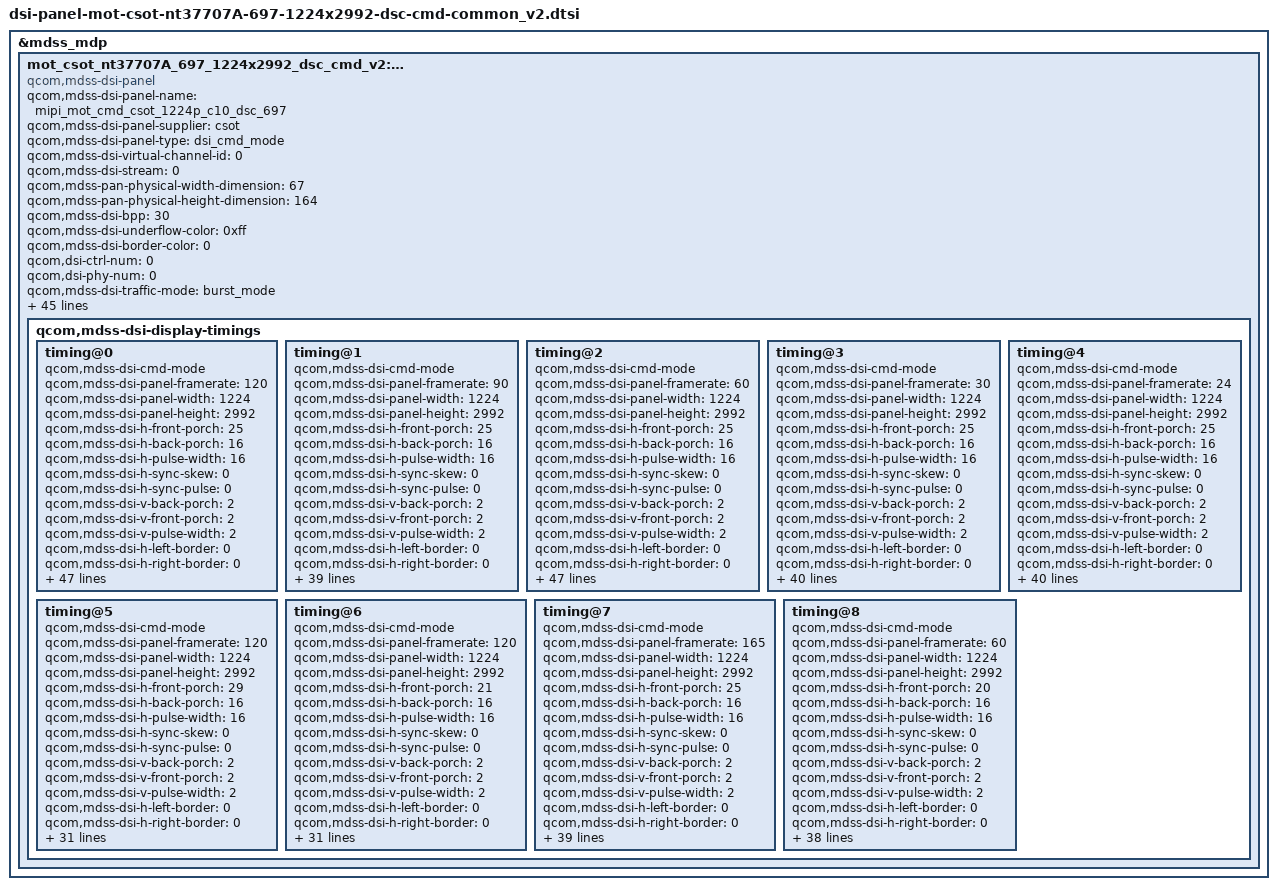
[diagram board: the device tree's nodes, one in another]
/* Copyright (c) 2019-2020, The Linux Foundation. All rights reserved.
 *
 * This program is free software; you can redistribute it and/or modify
 * it under the terms of the GNU General Public License version 2 and
 * only version 2 as published by the Free Software Foundation.
 *
 * This program is distributed in the hope that it will be useful,
 * but WITHOUT ANY WARRANTY; without even the implied warranty of
 * MERCHANTABILITY or FITNESS FOR A PARTICULAR PURPOSE.  See the
 * GNU General Public License for more details.
 */
&mdss_mdp {
mot_csot_nt37707A_697_1224x2992_dsc_cmd_v2: qcom,mdss_dsi_mot_csot_nt37707A_697_1224x2992_dsc_cmd_v2 {
compatible = "qcom,mdss-dsi-panel";
qcom,mdss-dsi-panel-name = "mipi_mot_cmd_csot_1224p_c10_dsc_697";
qcom,mdss-dsi-panel-supplier = "csot";
qcom,mdss-dsi-panel-type = "dsi_cmd_mode";
qcom,mdss-dsi-virtual-channel-id = <0>;
qcom,mdss-dsi-stream = <0>;
qcom,mdss-pan-physical-width-dimension = <67>;
qcom,mdss-pan-physical-height-dimension = <164>;
qcom,mdss-dsi-bpp = <30>;
qcom,mdss-dsi-underflow-color = <0xff>;
qcom,mdss-dsi-border-color = <0>;

qcom,dsi-ctrl-num = <0>;
qcom,dsi-phy-num = <0>;

qcom,mdss-dsi-traffic-mode = "burst_mode";
qcom,mdss-dsi-bllp-eof-power-mode;
qcom,mdss-dsi-bllp-power-mode;
qcom,mdss-dsi-lane-0-state;
qcom,mdss-dsi-lane-1-state;
qcom,mdss-dsi-lane-2-state;
qcom,mdss-dsi-lane-3-state;

qcom,mdss-dsi-dma-trigger = "trigger_sw";
qcom,mdss-dsi-mdp-trigger = "none";
qcom,mdss-dsi-reset-sequence = <0 3>, <1 1>, <0 1>, <1 20>;
qcom,mdss-dsi-lp11-init;
qcom,mdss-dsi-tx-eot-append;
qcom,mdss-dsi-te-pin-select = <1>;
qcom,mdss-dsi-te-dcs-command = <1>;
qcom,mdss-dsi-te-using-te-pin;

//qcom,bklt-dcs-2bytes-enabled;
qcom,mdss-dsi-bl-min-level = <4>;
qcom,mdss-dsi-bl-max-level = <14056>;
qcom,mdss-dsi-bl-pmic-control-type = "bl_ctrl_dcs";

qcom,mdss-dsi-panel-hdr-enabled;
qcom,mdss-dsi-panel-hdr-color-primaries = <14500 15500 32000
	        17000 15500 30000 8000 3000>;
qcom,mdss-dsi-panel-peak-brightness = <4200000>;

qcom,mdss-dsi-panel-blackness-level = <3230>;

qcom,mdss-dsi-dc-off-command = [
		39 00 00 40 00 00 02 6F 01
		39 00 00 40 00 00 02 8B 00
		39 00 00 00 00 00 03 6D 00 00
		];

qcom,mdss-dsi-dc-off-command-state = "dsi_hs_mode";
qcom,mdss-dsi-dc-on-command = [
		39 00 00 40 00 00 02 6F 01
		39 00 00 40 00 00 02 8B 81
		39 00 00 00 00 00 03 6D 00 00
		];
qcom,mdss-dsi-dc-on-command-state = "dsi_hs_mode";
//qcom,mdss-dsi-nt37705-dc-detect-fps;
qcom,check_pcd;
qcom,pcd-reg-read-enabled;
qcom,pcd-reg-check-before-read;
qcom,mdss-dsi-panel-pcd-reg-read-length = <1>;
qcom,mdss-dsi-panel-pcd-reg-mask = <0xFF>;
qcom,mdss-dsi-panel-pcd-reg-command = [06 01 00 01 00 00 01 D0];
qcom,mdss-dsi-panel-pcd-reg-pass-array-size = <4>;
qcom,mdss-dsi-panel-pcd-reg-pass-array = <0x80 0x81 0x82 0x83>;
qcom,mdss-dsi-panel-pcd-reg-read-delay-ms = <150>;
qcom,mdss-dsi-panel-pcd-reg-seq-interval = <30>; //pcd reg read seq interval per screen on.
qcom,mdss-dsi-panel-pcd-check-time-interval-in-minutes = <480>; //480 minutes/8hours for pcd reg read time interval

qcom,mdss-dsi-display-timings {
	timing@0{
		qcom,mdss-dsi-cmd-mode;
		qcom,mdss-dsi-panel-framerate = <120>;
		qcom,mdss-dsi-panel-width = <1224>;
		qcom,mdss-dsi-panel-height = <2992>;
		qcom,mdss-dsi-h-front-porch = <25>;
		qcom,mdss-dsi-h-back-porch = <16>;
		qcom,mdss-dsi-h-pulse-width = <16>;
		qcom,mdss-dsi-h-sync-skew = <0>;
		qcom,mdss-dsi-h-sync-pulse = <0>;
		qcom,mdss-dsi-v-back-porch = <2>;
		qcom,mdss-dsi-v-front-porch = <2>;
		qcom,mdss-dsi-v-pulse-width = <2>;
		qcom,mdss-dsi-h-left-border = <0>;
		qcom,mdss-dsi-h-right-border = <0>;
		qcom,mdss-dsi-v-top-border = <0>;
		qcom,mdss-dsi-v-bottom-border = <0>;
	        qcom,mdss-dsi-panel-jitter = <0x20 0xa>;
		qcom,mdss-dsi-timing-switch-command = [
			39 00 00 40 00 00 02 6B 00
			39 00 00 40 00 00 06 F0 55 AA 52 08 00
			39 00 00 40 00 00 02 6F CC
			39 00 00 40 00 00 02 B2 00 //exit MAFR
			39 00 00 40 00 00 02 6F 02
			39 00 00 40 00 00 02 8C 10
			39 00 00 40 00 00 02 8C 00
			39 00 00 40 00 00 02 6F 04
			39 00 00 40 00 00 02 35 00 //TE1=0
			39 00 00 40 00 00 02 53 20 //DBV Diming Disable
			39 00 00 00 00 00 02 2F 02 //120hz
		];
		qcom,mdss-dsi-on-command = [
			39 00 00 40 00 00 06 F0 55 AA 52 08 00
			39 00 00 40 00 00 02 6F 04
			39 00 00 40 00 00 05 C6 33 A3 33 33
			39 00 00 40 00 00 06 F0 55 AA 52 08 01
			39 00 00 40 00 00 02 6F 2F
			39 00 00 40 00 00 02 C3 44
			39 00 00 40 00 00 02 6F 00
			39 00 00 40 00 00 02 C3 DD
			39 00 00 40 00 00 02 6F 04
			39 00 00 40 00 00 02 C3 07
			39 00 00 40 00 00 02 6F 09
			39 00 00 40 00 00 02 C3 07
			39 00 00 40 00 00 06 F0 55 AA 52 08 00
			39 00 00 40 00 00 02 6F 04
			39 00 00 40 00 00 02 B1 07
			39 00 00 40 00 00 02 68 20
			39 00 00 40 00 00 06 F0 55 AA 52 08 09
			39 00 00 40 00 00 02 BD 05
			39 00 00 40 00 00 02 6F 10
			39 00 00 40 00 00 02 C1 00
			39 00 00 40 00 00 02 6F 11
			39 00 00 40 00 00 03 C1 00 0A
			39 00 00 40 00 00 02 6F 13
			39 00 00 40 00 00 03 C1 00 00
			39 00 00 40 00 00 02 6F 00
			39 00 00 40 00 00 06 C6 8A 8D 8D 90 90
			39 00 00 40 00 00 02 6F 05
			39 00 00 40 00 00 06 C6 89 85 83 8A 8A
			39 00 00 40 00 00 02 6F 0A
			39 00 00 40 00 00 06 C6 8A 83 89 84 8A
			39 00 00 40 00 00 02 6F 0F
			39 00 00 40 00 00 06 C6 85 83 83 84 85
			39 00 00 40 00 00 02 6F 14
			39 00 00 40 00 00 06 C6 84 84 85 84 83
			39 00 00 40 00 00 02 6F 19
			39 00 00 40 00 00 06 C6 83 84 83 84 83
			39 00 00 40 00 00 02 6F 1E
			39 00 00 40 00 00 06 C6 8A 8D 8D 90 90
			39 00 00 40 00 00 02 6F 23
			39 00 00 40 00 00 06 C6 89 85 83 8A 8A
			39 00 00 40 00 00 02 6F 28
			39 00 00 40 00 00 06 C6 8A 83 89 84 8A
			39 00 00 40 00 00 02 6F 2D
			39 00 00 40 00 00 06 C6 85 83 83 84 85
			39 00 00 40 00 00 02 6F 32
			39 00 00 40 00 00 06 C6 84 84 85 84 83
			39 00 00 40 00 00 02 6F 37
			39 00 00 40 00 00 06 C6 83 84 83 84 83
			39 00 00 40 00 00 02 6F 3C
			39 00 00 40 00 00 06 C6 8A 8D 8D 90 90
			39 00 00 40 00 00 02 6F 41
			39 00 00 40 00 00 06 C6 89 85 83 8A 8A
			39 00 00 40 00 00 02 6F 46
			39 00 00 40 00 00 06 C6 85 83 89 84 8A
			39 00 00 40 00 00 02 6F 4B
			39 00 00 40 00 00 06 C6 8A 83 83 84 85
			39 00 00 40 00 00 02 6F 50
			39 00 00 40 00 00 06 C6 84 84 85 84 83
			39 00 00 40 00 00 02 6F 55
			39 00 00 40 00 00 06 C6 83 84 83 84 83
			39 00 00 40 00 00 06 F0 55 AA 52 08 00
			39 00 00 40 00 00 02 6F 0D
			39 00 00 40 00 00 02 C2 1A
			39 00 00 40 00 00 06 F0 55 AA 52 08 04
			39 00 00 40 00 00 02 B1 00
			39 00 00 40 00 00 02 6F 0A
			39 00 00 40 00 00 02 B1 20
			39 00 00 40 00 00 02 6F 07
			39 00 00 40 00 00 04 B1 00 00 00
			39 00 00 40 00 00 02 6F 0B
			39 00 00 40 00 00 02 B1 00
			39 00 00 40 00 00 02 6F 06
			39 00 00 40 00 00 02 8D 05
			39 00 00 40 00 00 02 6F 01
			39 00 00 40 00 00 02 8D 20
			39 00 00 40 00 00 02 5A 01
			39 00 00 40 00 00 06 F0 55 AA 52 08 00
			39 00 00 40 00 00 02 6F 31
			39 00 00 40 00 00 04 C0 00 23 00
			39 00 00 40 00 00 02 6F 35
			39 00 00 40 00 00 04 C0 44 41 44
			39 00 00 40 00 00 06 F0 55 AA 52 08 04
			39 00 00 40 00 00 02 C0 20
			39 00 00 40 00 00 05 FF AA 55 A5 80
			39 00 00 40 00 00 02 6F 07
			39 00 00 40 00 00 02 F8 4D
			39 00 00 40 00 00 02 6F 23
			39 00 00 40 00 00 02 F8 4D
			39 00 00 40 00 00 05 FF AA 55 A5 81
			39 00 00 40 00 00 02 6F 21
			39 00 00 40 00 00 02 F5 03
			39 00 00 40 00 00 02 6F 43
			39 00 00 40 00 00 19 F5 01 02 01 04 00 01 02 00 00 00 43 02 00 00 10 00 00 10 05 00 11 31 12 11
			39 00 00 40 00 00 02 6F 1D
			39 00 00 40 00 00 04 FB 64 07 80
			39 00 00 40 00 00 02 6F 07
			39 00 00 40 00 00 02 FC 04
			39 00 00 40 00 00 02 6F 30
			39 00 00 40 00 00 02 FE 20
			39 00 00 40 00 00 05 FF AA 55 A5 84
			39 00 00 40 00 00 02 6F 9A
			39 00 00 40 00 00 02 F3 0F
			39 00 00 40 00 00 02 6F 9F
			39 00 00 40 00 00 02 F4 00
			39 00 00 40 00 00 02 6F E9
			39 00 00 40 00 00 02 F4 03
			39 00 00 40 00 00 02 6F 28
			39 00 00 40 00 00 02 F8 00
			39 00 00 40 00 00 05 FF AA 55 A5 81
			39 00 00 40 00 00 02 6F 0F
			39 00 00 40 00 00 02 F5 0E
			39 00 00 40 00 00 06 F0 55 AA 52 08 00
			39 00 00 40 00 00 02 6F 78
			39 00 00 40 00 00 18 B0 10 00 2A 00 C2 01 DA 03 7C 05 B1 08 80 0B EE 0F FF 05 55 05 56 05 55
			39 00 00 40 00 00 02 6F 6F
			39 00 00 40 00 00 07 B0 02 64 04 C8 02 64
			39 00 00 40 00 00 06 F0 55 AA 52 08 08
			39 00 00 40 00 00 17 C1 8D FF DD FF FF DD FF FF DD FF FF DD FF FF EE FF FF AA 7C 1E 0E FF
			39 00 00 40 00 00 02 6F 23
			39 00 00 40 00 00 15 C1 0D FF DD FF FF DD FF FF DD FF FF DD FF FF EE FF FF AA 7C 1E
			39 00 00 40 00 00 02 6F 37
			39 00 00 40 00 00 15 C1 0D FF DD FF FF DD FF FF DD FF FF DD FF FF EE FF FF FF FF FF
			39 00 00 40 00 00 02 6F 4B
			39 00 00 40 00 00 15 C1 0D FF DD FF FF DD FF FF DD FF FF DD FF FF EE FF FF AA 7C 1E
			39 00 00 40 00 00 02 6F 5F
			39 00 00 40 00 00 15 C1 0D FF DD FF FF DD FF FF DD FF FF DD FF FF EE FF FF FF FF FF
			39 00 00 40 00 00 02 6F 73
			39 00 00 40 00 00 15 C1 0D FF DD FF FF DD FF FF DD FF FF DD FF FF EE FF FF AA 7C 1E
			39 00 00 40 00 00 11 BA 00 04 03 A4 03 A4 05 B8 05 B8 07 D8 07 D8 0A 84
			39 00 00 40 00 00 02 6F 10
			39 00 00 40 00 00 11 BA 0A 84 0D C3 0D C3 0D C4 0D C4 1D 24 1D 24 2C 50
			39 00 00 40 00 00 02 6F 20
			39 00 00 40 00 00 0d BA 2C 50 36 E8 36 E8 3A FE 3A FE 3F FC
			39 00 00 40 00 00 02 6F 20
			39 00 00 40 00 00 04 C1 04 52 CD
			39 00 00 40 00 00 02 6F 1D
			39 00 00 40 00 00 04 C1 00 80 FF
			39 00 00 40 00 00 02 6F 07
			39 00 00 40 00 00 02 51 00
			39 00 00 40 00 00 05 FF AA 55 A5 81
			39 00 00 40 00 00 02 6F 02
			39 00 00 40 00 00 02 F9 04
			39 00 00 40 00 00 05 FF AA 55 A5 81
			39 00 00 40 00 00 02 6F 0D
			39 00 00 40 00 00 02 FB 80
			39 00 00 40 00 00 05 FF AA 55 A5 81
			39 00 00 40 00 00 02 6F 10
			39 00 00 40 00 00 02 FB 40
			39 00 00 40 00 00 05 FF AA 55 A5 81
			39 00 00 40 00 00 02 6F 0C
			39 00 00 40 00 00 02 FD 08
			39 00 00 40 00 00 05 FF AA 55 A5 81
			39 00 00 40 00 00 02 6F 05
			39 00 00 40 00 00 03 FE 3C 3C
			39 00 00 40 00 00 05 FF AA 55 A5 80
			39 00 00 40 00 00 02 6F 0A
			39 00 00 40 00 00 06 F6 70 70 70 70 70
			39 00 00 40 00 00 05 2A 00 00 04 C7
			39 00 00 40 00 00 05 2B 00 00 0B AF
			39 00 00 40 00 00 02 2F 02
			39 00 00 40 00 00 03 5F 00 00
			39 00 00 40 00 00 02 35 00
			39 00 00 40 00 00 02 6F 02
			39 00 00 40 00 00 02 8C 10
			39 00 00 40 00 00 02 8C 00
			39 00 00 40 00 00 02 6F 04
			39 00 00 40 00 00 02 35 00
			39 00 00 40 00 00 03 51 00 00
			39 00 00 40 00 00 02 6F 04
			39 00 00 40 00 00 03 51 00 00
			39 00 00 40 00 00 02 53 20
			39 00 00 40 00 00 02 90 03
			39 00 00 40 00 00 02 6F 01
			39 00 00 40 00 00 02 90 43
			39 00 00 00 00 00 13 91 AB 28 00 10 C2 00 02 32 01 9C 00 08 06 67 05 9C 10 F0
                	05 00 00 00 78 00 01 11
                	05 00 00 00 00 00 01 29];	/* display on */
		qcom,mdss-dsi-off-command = [
			05 00 00 00 00 00 01 28		/* display_off */
			05 00 00 00 64 00 01 10];	/* enter sleep mode */

		qcom,mdss-dsi-on-command-state = "dsi_lp_mode";
		qcom,mdss-dsi-off-command-state = "dsi_lp_mode";
		qcom,mdss-dsi-timing-switch-command-state =
			"dsi_lp_mode";
		qcom,compression-mode = "dsc";
		/* Why QCOM doesn't use this, even it used 2 encoder
		 * as for that dsi_sw43404_amoled_cmd, for ex */
		/* qcom,mdss-dsc-encoders = <2>; */
		qcom,mdss-dsc-version = <0x11>;
		qcom,mdss-dsc-slice-height = <16>;
		qcom,mdss-dsc-slice-width = <612>;
		qcom,mdss-dsc-slice-per-pkt = <2>;
		qcom,mdss-dsc-bit-per-component = <10>;
		qcom,mdss-dsc-bit-per-pixel = <8>;
		qcom,mdss-dsc-block-prediction-enable;
		qcom,mdss-dsc-novateck-ic;
		qcom,mdss-dsi-pcd-check-enable-command = [
			39 00 00 40 00 00 06 F0 55 AA 52 08 06
			39 00 00 40 00 00 03 B1 35 35
			39 00 00 40 00 00 02 6F 01
			39 00 00 40 00 00 02 B2 37
			39 00 00 40 00 00 03 B7 35 35
			39 00 00 40 00 00 02 6F 01
			39 00 00 40 00 00 02 B8 37
			39 00 00 40 00 00 05 FF AA 55 A5 80
			39 00 00 40 00 00 02 6F 12
			39 00 00 40 00 00 04 F4 01 0C 11
			39 00 00 00 00 00 02 9B 00];

		qcom,mdss-dsi-pcd-check-enable-command-state = "dsi_hs_mode";
		qcom,mdss-dsi-pcd-check-disable-command = [
			39 00 00 40 00 00 06 F0 55 AA 52 08 06
			39 00 00 40 00 00 03 B1 37 37
			39 00 00 40 00 00 02 6F 01
			39 00 00 40 00 00 02 B2 36
			39 00 00 40 00 00 03 B7 37 37
			39 00 00 40 00 00 02 6F 01
			39 00 00 40 00 00 02 B8 36
			39 00 00 40 00 00 05 FF AA 55 A5 80
			39 00 00 40 00 00 02 6F 12
			39 00 00 40 00 00 04 F4 00 00 00
			39 00 00 00 00 00 02 9B 01];
		qcom,mdss-dsi-pcd-check-disable-command-state = "dsi_hs_mode";
		qcom,mdss-dsi-pcd-check-in-enable-command = [
			39 00 00 40 00 00 06 F0 55 AA 52 08 01
			39 00 00 00 00 00 03 D0 00 80
			];
		qcom,mdss-dsi-pcd-check-in-enable-command-state = "dsi_hs_mode";
		qcom,mdss-dsi-pcd-check-in-disable-command = [
			39 00 00 40 00 00 06 F0 55 AA 52 08 01
			39 00 00 00 00 00 03 D0 00 00
			];
		qcom,mdss-dsi-pcd-check-in-disable-command-state = "dsi_hs_mode";
		qcom,mdss-dsi-lp1-command = [
			39 00 00 40 00 00 02 6B 00
			39 00 00 40 00 00 06 F0 55 AA 52 08 00
			39 00 00 40 00 00 02 6F CC
			39 00 00 40 00 00 02 B2 00 //exit MAFR
			39 00 00 40 00 00 02 6F 02
			39 00 00 40 00 00 02 8C 10
			39 00 00 40 00 00 02 8C 00
			39 00 00 40 00 00 02 6F 04
			39 00 00 40 00 00 02 35 00 //TE1=0
			39 00 00 40 00 00 02 53 20 //DBV Diming Disable
			39 00 00 00 00 00 02 2F 02 //120hz
		];
		qcom,mdss-dsi-lp1-command-state =
			"dsi_lp_mode";
		qcom,mdss-dsi-lp2-command = [
			39 00 00 40 00 00 02 6B 00
			39 00 00 40 00 00 06 F0 55 AA 52 08 00
			39 00 00 40 00 00 02 6F CC
			39 00 00 40 00 00 02 B2 00 //exit MAFR
			39 00 00 40 00 00 02 6F 04
			39 00 00 40 00 00 02 35 00 //TE = 1
			39 00 00 40 00 00 02 53 20 //DBV Diming Enable
			39 00 00 40 00 00 02 5A 00
			39 00 00 40 00 00 02 6F 06
			39 00 00 40 00 00 02 6D 00
			39 00 00 40 00 00 02 2F 30
			39 00 00 40 00 00 03 6D 04 00
			39 00 00 40 00 00 02 6F 02
			39 00 00 40 00 00 02 8C 10
			39 00 00 00 00 00 02 8C 00
		];
		qcom,mdss-dsi-lp2-command-state =
			"dsi_lp_mode";
		qcom,mdss-dsi-nolp-command = [
			39 00 00 40 00 00 02 6B 00
			39 00 00 40 00 00 06 F0 55 AA 52 08 00
			39 00 00 40 00 00 02 6F CC
			39 00 00 40 00 00 02 B2 00 //exit MAFR
			39 00 00 40 00 00 02 6F 02
			39 00 00 40 00 00 02 8C 10
			39 00 00 40 00 00 02 8C 00
			39 00 00 40 00 00 02 6F 04
			39 00 00 40 00 00 02 35 00 //TE1=0
			39 00 00 40 00 00 02 53 20 //DBV Diming Disable
			39 00 00 00 00 00 02 2F 02 //120hz
		];
		qcom,mdss-dsi-nolp-command-state =
			"dsi_lp_mode";
	};

	timing@1{
		qcom,mdss-dsi-cmd-mode;
		qcom,mdss-dsi-panel-framerate = <90>;
		qcom,mdss-dsi-panel-width = <1224>;
		qcom,mdss-dsi-panel-height = <2992>;
		qcom,mdss-dsi-h-front-porch = <25>;
		qcom,mdss-dsi-h-back-porch = <16>;
		qcom,mdss-dsi-h-pulse-width = <16>;
		qcom,mdss-dsi-h-sync-skew = <0>;
		qcom,mdss-dsi-h-sync-pulse = <0>;
		qcom,mdss-dsi-v-back-porch = <2>;
		qcom,mdss-dsi-v-front-porch = <2>;
		qcom,mdss-dsi-v-pulse-width = <2>;
		qcom,mdss-dsi-h-left-border = <0>;
		qcom,mdss-dsi-h-right-border = <0>;
		qcom,mdss-dsi-v-top-border = <0>;
		qcom,mdss-dsi-v-bottom-border = <0>;
	        qcom,mdss-dsi-panel-jitter = <0x20 0xa>;
		qcom,mdss-dsi-timing-switch-command = [
			39 00 00 40 00 00 02 6B 00
			39 00 00 40 00 00 06 F0 55 AA 52 08 00
			39 00 00 40 00 00 02 6F CC
			39 00 00 40 00 00 02 B2 00 //exit MAFR
			39 00 00 40 00 00 02 6F 02
			39 00 00 40 00 00 02 8C 10
			39 00 00 40 00 00 02 8C 00
			39 00 00 40 00 00 02 6F 04
			39 00 00 40 00 00 02 35 00 //TE1=0
			39 00 00 40 00 00 02 53 20 //DBV Diming Disable
			39 00 00 00 0B 00 02 2F 04 //90hz
		];
		qcom,mdss-dsi-on-command = [
			39 00 00 40 00 00 06 F0 55 AA 52 08 00
			39 00 00 40 00 00 02 6F 04
			39 00 00 40 00 00 05 C6 33 A3 33 33
			39 00 00 40 00 00 06 F0 55 AA 52 08 01
			39 00 00 40 00 00 02 6F 2F
			39 00 00 40 00 00 02 C3 44
			39 00 00 40 00 00 02 6F 00
			39 00 00 40 00 00 02 C3 DD
			39 00 00 40 00 00 02 6F 04
			39 00 00 40 00 00 02 C3 07
			39 00 00 40 00 00 02 6F 09
			39 00 00 40 00 00 02 C3 07
			39 00 00 40 00 00 06 F0 55 AA 52 08 00
			39 00 00 40 00 00 02 6F 04
			39 00 00 40 00 00 02 B1 07
			39 00 00 40 00 00 02 68 20
			39 00 00 40 00 00 06 F0 55 AA 52 08 09
			39 00 00 40 00 00 02 BD 05
			39 00 00 40 00 00 02 6F 10
			39 00 00 40 00 00 02 C1 00
			39 00 00 40 00 00 02 6F 11
			39 00 00 40 00 00 03 C1 00 0A
			39 00 00 40 00 00 02 6F 13
			39 00 00 40 00 00 03 C1 00 00
			39 00 00 40 00 00 02 6F 00
			39 00 00 40 00 00 06 C6 8A 8D 8D 90 90
			39 00 00 40 00 00 02 6F 05
			39 00 00 40 00 00 06 C6 89 85 83 8A 8A
			39 00 00 40 00 00 02 6F 0A
			39 00 00 40 00 00 06 C6 8A 83 89 84 8A
			39 00 00 40 00 00 02 6F 0F
			39 00 00 40 00 00 06 C6 85 83 83 84 85
			39 00 00 40 00 00 02 6F 14
			39 00 00 40 00 00 06 C6 84 84 85 84 83
			39 00 00 40 00 00 02 6F 19
			39 00 00 40 00 00 06 C6 83 84 83 84 83
			39 00 00 40 00 00 02 6F 1E
			39 00 00 40 00 00 06 C6 8A 8D 8D 90 90
			39 00 00 40 00 00 02 6F 23
			39 00 00 40 00 00 06 C6 89 85 83 8A 8A
			39 00 00 40 00 00 02 6F 28
			39 00 00 40 00 00 06 C6 8A 83 89 84 8A
			39 00 00 40 00 00 02 6F 2D
			39 00 00 40 00 00 06 C6 85 83 83 84 85
			39 00 00 40 00 00 02 6F 32
			39 00 00 40 00 00 06 C6 84 84 85 84 83
			39 00 00 40 00 00 02 6F 37
			39 00 00 40 00 00 06 C6 83 84 83 84 83
			39 00 00 40 00 00 02 6F 3C
			39 00 00 40 00 00 06 C6 8A 8D 8D 90 90
			39 00 00 40 00 00 02 6F 41
			39 00 00 40 00 00 06 C6 89 85 83 8A 8A
			39 00 00 40 00 00 02 6F 46
			39 00 00 40 00 00 06 C6 85 83 89 84 8A
			39 00 00 40 00 00 02 6F 4B
			39 00 00 40 00 00 06 C6 8A 83 83 84 85
			39 00 00 40 00 00 02 6F 50
			39 00 00 40 00 00 06 C6 84 84 85 84 83
			39 00 00 40 00 00 02 6F 55
			39 00 00 40 00 00 06 C6 83 84 83 84 83
			39 00 00 40 00 00 06 F0 55 AA 52 08 00
			39 00 00 40 00 00 02 6F 0D
			39 00 00 40 00 00 02 C2 1A
			39 00 00 40 00 00 06 F0 55 AA 52 08 04
			39 00 00 40 00 00 02 B1 00
			39 00 00 40 00 00 02 6F 0A
			39 00 00 40 00 00 02 B1 20
			39 00 00 40 00 00 02 6F 07
			39 00 00 40 00 00 04 B1 00 00 00
			39 00 00 40 00 00 02 6F 0B
			39 00 00 40 00 00 02 B1 00
			39 00 00 40 00 00 02 6F 06
			39 00 00 40 00 00 02 8D 05
			39 00 00 40 00 00 02 6F 01
			39 00 00 40 00 00 02 8D 20
			39 00 00 40 00 00 02 5A 01
			39 00 00 40 00 00 06 F0 55 AA 52 08 00
			39 00 00 40 00 00 02 6F 31
			39 00 00 40 00 00 04 C0 00 23 00
			39 00 00 40 00 00 02 6F 35
			39 00 00 40 00 00 04 C0 44 41 44
			39 00 00 40 00 00 06 F0 55 AA 52 08 04
			39 00 00 40 00 00 02 C0 20
			39 00 00 40 00 00 05 FF AA 55 A5 80
			39 00 00 40 00 00 02 6F 07
			39 00 00 40 00 00 02 F8 4D
			39 00 00 40 00 00 02 6F 23
			39 00 00 40 00 00 02 F8 4D
			39 00 00 40 00 00 05 FF AA 55 A5 81
			39 00 00 40 00 00 02 6F 21
			39 00 00 40 00 00 02 F5 03
			39 00 00 40 00 00 02 6F 43
			39 00 00 40 00 00 19 F5 01 02 01 04 00 01 02 00 00 00 43 02 00 00 10 00 00 10 05 00 11 31 12 11
			39 00 00 40 00 00 02 6F 1D
			39 00 00 40 00 00 04 FB 64 07 80
			39 00 00 40 00 00 02 6F 07
			39 00 00 40 00 00 02 FC 04
			39 00 00 40 00 00 02 6F 30
			39 00 00 40 00 00 02 FE 20
			39 00 00 40 00 00 05 FF AA 55 A5 84
			39 00 00 40 00 00 02 6F 9A
			39 00 00 40 00 00 02 F3 0F
			39 00 00 40 00 00 02 6F 9F
			39 00 00 40 00 00 02 F4 00
			39 00 00 40 00 00 02 6F E9
			39 00 00 40 00 00 02 F4 03
			39 00 00 40 00 00 02 6F 28
			39 00 00 40 00 00 02 F8 00
			39 00 00 40 00 00 05 FF AA 55 A5 81
			39 00 00 40 00 00 02 6F 0F
			39 00 00 40 00 00 02 F5 0E
			39 00 00 40 00 00 06 F0 55 AA 52 08 00
			39 00 00 40 00 00 02 6F 78
			39 00 00 40 00 00 18 B0 10 00 2A 00 C2 01 DA 03 7C 05 B1 08 80 0B EE 0F FF 05 55 05 56 05 55
			39 00 00 40 00 00 02 6F 6F
			39 00 00 40 00 00 07 B0 02 64 04 C8 02 64
			39 00 00 40 00 00 06 F0 55 AA 52 08 08
			39 00 00 40 00 00 17 C1 8D FF DD FF FF DD FF FF DD FF FF DD FF FF EE FF FF AA 7C 1E 0E FF
			39 00 00 40 00 00 02 6F 23
			39 00 00 40 00 00 15 C1 0D FF DD FF FF DD FF FF DD FF FF DD FF FF EE FF FF AA 7C 1E
			39 00 00 40 00 00 02 6F 37
			39 00 00 40 00 00 15 C1 0D FF DD FF FF DD FF FF DD FF FF DD FF FF EE FF FF FF FF FF
			39 00 00 40 00 00 02 6F 4B
			39 00 00 40 00 00 15 C1 0D FF DD FF FF DD FF FF DD FF FF DD FF FF EE FF FF AA 7C 1E
			39 00 00 40 00 00 02 6F 5F
			39 00 00 40 00 00 15 C1 0D FF DD FF FF DD FF FF DD FF FF DD FF FF EE FF FF FF FF FF
			39 00 00 40 00 00 02 6F 73
			39 00 00 40 00 00 15 C1 0D FF DD FF FF DD FF FF DD FF FF DD FF FF EE FF FF AA 7C 1E
			39 00 00 40 00 00 11 BA 00 04 03 A4 03 A4 05 B8 05 B8 07 D8 07 D8 0A 84
			39 00 00 40 00 00 02 6F 10
			39 00 00 40 00 00 11 BA 0A 84 0D C3 0D C3 0D C4 0D C4 1D 24 1D 24 2C 50
			39 00 00 40 00 00 02 6F 20
			39 00 00 40 00 00 0d BA 2C 50 36 E8 36 E8 3A FE 3A FE 3F FC
			39 00 00 40 00 00 02 6F 20
			39 00 00 40 00 00 04 C1 04 52 CD
			39 00 00 40 00 00 02 6F 1D
			39 00 00 40 00 00 04 C1 00 80 FF
			39 00 00 40 00 00 02 6F 07
			39 00 00 40 00 00 02 51 00
			39 00 00 40 00 00 05 FF AA 55 A5 81
			39 00 00 40 00 00 02 6F 02
			39 00 00 40 00 00 02 F9 04
			39 00 00 40 00 00 05 FF AA 55 A5 81
			39 00 00 40 00 00 02 6F 0D
			39 00 00 40 00 00 02 FB 80
			39 00 00 40 00 00 05 FF AA 55 A5 81
			39 00 00 40 00 00 02 6F 10
			39 00 00 40 00 00 02 FB 40
			39 00 00 40 00 00 05 FF AA 55 A5 81
			39 00 00 40 00 00 02 6F 0C
			39 00 00 40 00 00 02 FD 08
			39 00 00 40 00 00 05 FF AA 55 A5 81
			39 00 00 40 00 00 02 6F 05
			39 00 00 40 00 00 03 FE 3C 3C
			39 00 00 40 00 00 05 FF AA 55 A5 80
			39 00 00 40 00 00 02 6F 0A
			39 00 00 40 00 00 06 F6 70 70 70 70 70
			39 00 00 40 00 00 05 2A 00 00 04 C7
			39 00 00 40 00 00 05 2B 00 00 0B AF
			39 00 00 40 00 00 02 2F 04
			39 00 00 40 00 00 03 5F 00 00
			39 00 00 40 00 00 02 35 00
			39 00 00 40 00 00 02 6F 02
			39 00 00 40 00 00 02 8C 10
			39 00 00 40 00 00 02 8C 00
			39 00 00 40 00 00 02 6F 04
			39 00 00 40 00 00 02 35 00
			39 00 00 40 00 00 03 51 00 00
			39 00 00 40 00 00 02 6F 04
			39 00 00 40 00 00 03 51 00 00
			39 00 00 40 00 00 02 53 20
			39 00 00 40 00 00 02 90 03
			39 00 00 40 00 00 02 6F 01
			39 00 00 40 00 00 02 90 43
			39 00 00 00 00 00 13 91 AB 28 00 10 C2 00 02 32 01 9C 00 08 06 67 05 9C 10 F0
                	05 00 00 00 78 00 01 11
                	05 00 00 00 00 00 01 29];	/* display on */
		qcom,mdss-dsi-off-command = [
			05 00 00 00 00 00 01 28		/* display_off */
			05 00 00 00 64 00 01 10];	/* enter sleep mode */

		qcom,mdss-dsi-on-command-state = "dsi_lp_mode";
		qcom,mdss-dsi-off-command-state = "dsi_lp_mode";
		qcom,mdss-dsi-timing-switch-command-state =
			"dsi_lp_mode";
		qcom,compression-mode = "dsc";
		/* Why QCOM doesn't use this, even it used 2 encoder
		 * as for that dsi_sw43404_amoled_cmd, for ex */
		/* qcom,mdss-dsc-encoders = <2>; */
		qcom,mdss-dsc-version = <0x11>;
		qcom,mdss-dsc-slice-height = <16>;
		qcom,mdss-dsc-slice-width = <612>;
		qcom,mdss-dsc-slice-per-pkt = <2>;
		qcom,mdss-dsc-bit-per-component = <10>;
		qcom,mdss-dsc-bit-per-pixel = <8>;
		qcom,mdss-dsc-block-prediction-enable;
		qcom,mdss-dsc-novateck-ic;
		qcom,mdss-dsi-pcd-check-in-enable-command = [
			39 00 00 40 00 00 06 F0 55 AA 52 08 01
			39 00 00 00 00 00 03 D0 00 80
			];
		qcom,mdss-dsi-pcd-check-in-enable-command-state = "dsi_hs_mode";
		qcom,mdss-dsi-pcd-check-in-disable-command = [
			39 00 00 40 00 00 06 F0 55 AA 52 08 01
			39 00 00 00 00 00 03 D0 00 00
			];
		qcom,mdss-dsi-pcd-check-in-disable-command-state = "dsi_hs_mode";
		qcom,mdss-dsi-lp1-command = [
			39 00 00 40 00 00 02 6B 00
			39 00 00 40 00 00 06 F0 55 AA 52 08 00
			39 00 00 40 00 00 02 6F CC
			39 00 00 40 00 00 02 B2 00 //exit MAFR
			39 00 00 40 00 00 02 6F 02
			39 00 00 40 00 00 02 8C 10
			39 00 00 40 00 00 02 8C 00
			39 00 00 40 00 00 02 6F 04
			39 00 00 40 00 00 02 35 00 //TE1=0
			39 00 00 40 00 00 02 53 20 //DBV Diming Disable
			39 00 00 00 0B 00 02 2F 04 //90hz
		];
		qcom,mdss-dsi-lp1-command-state =
			"dsi_lp_mode";
		qcom,mdss-dsi-lp2-command = [
			39 00 00 40 00 00 02 6B 00
			39 00 00 40 00 00 06 F0 55 AA 52 08 00
			39 00 00 40 00 00 02 6F CC
			39 00 00 40 00 00 02 B2 00 //exit MAFR
			39 00 00 40 00 00 02 6F 04
			39 00 00 40 00 00 02 35 00 //TE = 1
			39 00 00 40 00 00 02 53 20 //DBV Diming Enable
			39 00 00 40 00 00 02 5A 00
			39 00 00 40 00 00 02 6F 06
			39 00 00 40 00 00 02 6D 00
			39 00 00 40 00 00 02 2F 30
			39 00 00 40 00 00 03 6D 04 00
			39 00 00 40 00 00 02 6F 02
			39 00 00 40 00 00 02 8C 10
			39 00 00 00 00 00 02 8C 00
		];
		qcom,mdss-dsi-lp2-command-state =
			"dsi_lp_mode";
		qcom,mdss-dsi-nolp-command = [
			39 00 00 40 00 00 02 6B 00
			39 00 00 40 00 00 06 F0 55 AA 52 08 00
			39 00 00 40 00 00 02 6F CC
			39 00 00 40 00 00 02 B2 00 //exit MAFR
			39 00 00 40 00 00 02 6F 02
			39 00 00 40 00 00 02 8C 10
			39 00 00 40 00 00 02 8C 00
			39 00 00 40 00 00 02 6F 04
			39 00 00 40 00 00 02 35 00 //TE1=0
			39 00 00 40 00 00 02 53 20 //DBV Diming Disable
			39 00 00 00 0B 00 02 2F 04 //90hz
		];
		qcom,mdss-dsi-nolp-command-state =
			"dsi_lp_mode";
	};

	timing@2{
		qcom,mdss-dsi-cmd-mode;
		qcom,mdss-dsi-panel-framerate = <60>;
		qcom,mdss-dsi-panel-width = <1224>;
		qcom,mdss-dsi-panel-height = <2992>;
		qcom,mdss-dsi-h-front-porch = <25>;
		qcom,mdss-dsi-h-back-porch = <16>;
		qcom,mdss-dsi-h-pulse-width = <16>;
		qcom,mdss-dsi-h-sync-skew = <0>;
		qcom,mdss-dsi-h-sync-pulse = <0>;
		qcom,mdss-dsi-v-back-porch = <2>;
		qcom,mdss-dsi-v-front-porch = <2>;
		qcom,mdss-dsi-v-pulse-width = <2>;
		qcom,mdss-dsi-h-left-border = <0>;
		qcom,mdss-dsi-h-right-border = <0>;
		qcom,mdss-dsi-v-top-border = <0>;
		qcom,mdss-dsi-v-bottom-border = <0>;
		qcom,mdss-dsi-panel-jitter = <0x20 0xa>;
		qcom,mdss-dsi-timing-switch-command = [
			39 00 00 40 00 00 02 6B 00
			39 00 00 40 00 00 06 F0 55 AA 52 08 00
			39 00 00 40 00 00 02 6F CC
			39 00 00 40 00 00 02 B2 00 //exit MAFR
			39 00 00 40 00 00 02 6F 04
			39 00 00 40 00 00 02 35 00
			39 00 00 40 00 00 02 53 20
			39 00 00 40 00 00 02 5A 02
			39 00 00 40 00 00 02 2F 30
			39 00 00 40 00 00 03 6D 00 00
			39 00 00 40 00 00 02 6F 06
			39 00 00 40 00 00 02 6D 03
			39 00 00 40 00 00 02 6F 02
			39 00 00 40 00 00 02 8C 10
			39 00 00 00 11 00 02 8C 02
		];
		qcom,mdss-dsi-on-command = [
			39 00 00 40 00 00 06 F0 55 AA 52 08 00
			39 00 00 40 00 00 02 6F 04
			39 00 00 40 00 00 05 C6 33 A3 33 33
			39 00 00 40 00 00 06 F0 55 AA 52 08 01
			39 00 00 40 00 00 02 6F 2F
			39 00 00 40 00 00 02 C3 44
			39 00 00 40 00 00 02 6F 00
			39 00 00 40 00 00 02 C3 DD
			39 00 00 40 00 00 02 6F 04
			39 00 00 40 00 00 02 C3 07
			39 00 00 40 00 00 02 6F 09
			39 00 00 40 00 00 02 C3 07
			39 00 00 40 00 00 06 F0 55 AA 52 08 00
			39 00 00 40 00 00 02 6F 04
			39 00 00 40 00 00 02 B1 07
			39 00 00 40 00 00 02 68 20
			39 00 00 40 00 00 06 F0 55 AA 52 08 09
			39 00 00 40 00 00 02 BD 05
			39 00 00 40 00 00 02 6F 10
			39 00 00 40 00 00 02 C1 00
			39 00 00 40 00 00 02 6F 11
			39 00 00 40 00 00 03 C1 00 0A
			39 00 00 40 00 00 02 6F 13
			39 00 00 40 00 00 03 C1 00 00
			39 00 00 40 00 00 02 6F 00
			39 00 00 40 00 00 06 C6 8A 8D 8D 90 90
			39 00 00 40 00 00 02 6F 05
			39 00 00 40 00 00 06 C6 89 85 83 8A 8A
			39 00 00 40 00 00 02 6F 0A
			39 00 00 40 00 00 06 C6 8A 83 89 84 8A
			39 00 00 40 00 00 02 6F 0F
			39 00 00 40 00 00 06 C6 85 83 83 84 85
			39 00 00 40 00 00 02 6F 14
			39 00 00 40 00 00 06 C6 84 84 85 84 83
			39 00 00 40 00 00 02 6F 19
			39 00 00 40 00 00 06 C6 83 84 83 84 83
			39 00 00 40 00 00 02 6F 1E
			39 00 00 40 00 00 06 C6 8A 8D 8D 90 90
			39 00 00 40 00 00 02 6F 23
			39 00 00 40 00 00 06 C6 89 85 83 8A 8A
			39 00 00 40 00 00 02 6F 28
			39 00 00 40 00 00 06 C6 8A 83 89 84 8A
			39 00 00 40 00 00 02 6F 2D
			39 00 00 40 00 00 06 C6 85 83 83 84 85
			39 00 00 40 00 00 02 6F 32
			39 00 00 40 00 00 06 C6 84 84 85 84 83
			39 00 00 40 00 00 02 6F 37
			39 00 00 40 00 00 06 C6 83 84 83 84 83
			39 00 00 40 00 00 02 6F 3C
			39 00 00 40 00 00 06 C6 8A 8D 8D 90 90
			39 00 00 40 00 00 02 6F 41
			39 00 00 40 00 00 06 C6 89 85 83 8A 8A
			39 00 00 40 00 00 02 6F 46
			39 00 00 40 00 00 06 C6 85 83 89 84 8A
			39 00 00 40 00 00 02 6F 4B
			39 00 00 40 00 00 06 C6 8A 83 83 84 85
			39 00 00 40 00 00 02 6F 50
			39 00 00 40 00 00 06 C6 84 84 85 84 83
			39 00 00 40 00 00 02 6F 55
			39 00 00 40 00 00 06 C6 83 84 83 84 83
			39 00 00 40 00 00 06 F0 55 AA 52 08 00
			39 00 00 40 00 00 02 6F 0D
			39 00 00 40 00 00 02 C2 1A
			39 00 00 40 00 00 06 F0 55 AA 52 08 04
			39 00 00 40 00 00 02 B1 00
			39 00 00 40 00 00 02 6F 0A
			39 00 00 40 00 00 02 B1 20
			39 00 00 40 00 00 02 6F 07
			39 00 00 40 00 00 04 B1 00 00 00
			39 00 00 40 00 00 02 6F 0B
			39 00 00 40 00 00 02 B1 00
			39 00 00 40 00 00 02 6F 06
			39 00 00 40 00 00 02 8D 05
			39 00 00 40 00 00 02 6F 01
			39 00 00 40 00 00 02 8D 20
			39 00 00 40 00 00 02 5A 01
			39 00 00 40 00 00 06 F0 55 AA 52 08 00
			39 00 00 40 00 00 02 6F 31
			39 00 00 40 00 00 04 C0 00 23 00
			39 00 00 40 00 00 02 6F 35
			39 00 00 40 00 00 04 C0 44 41 44
			39 00 00 40 00 00 06 F0 55 AA 52 08 04
			39 00 00 40 00 00 02 C0 20
			39 00 00 40 00 00 05 FF AA 55 A5 80
			39 00 00 40 00 00 02 6F 07
			39 00 00 40 00 00 02 F8 4D
			39 00 00 40 00 00 02 6F 23
			39 00 00 40 00 00 02 F8 4D
			39 00 00 40 00 00 05 FF AA 55 A5 81
			39 00 00 40 00 00 02 6F 21
			39 00 00 40 00 00 02 F5 03
			39 00 00 40 00 00 02 6F 43
			39 00 00 40 00 00 19 F5 01 02 01 04 00 01 02 00 00 00 43 02 00 00 10 00 00 10 05 00 11 31 12 11
			39 00 00 40 00 00 02 6F 1D
			39 00 00 40 00 00 04 FB 64 07 80
			39 00 00 40 00 00 02 6F 07
			39 00 00 40 00 00 02 FC 04
			39 00 00 40 00 00 02 6F 30
			39 00 00 40 00 00 02 FE 20
			39 00 00 40 00 00 05 FF AA 55 A5 84
			39 00 00 40 00 00 02 6F 9A
			39 00 00 40 00 00 02 F3 0F
			39 00 00 40 00 00 02 6F 9F
			39 00 00 40 00 00 02 F4 00
			39 00 00 40 00 00 02 6F E9
			39 00 00 40 00 00 02 F4 03
			39 00 00 40 00 00 02 6F 28
			39 00 00 40 00 00 02 F8 00
			39 00 00 40 00 00 05 FF AA 55 A5 81
			39 00 00 40 00 00 02 6F 0F
			39 00 00 40 00 00 02 F5 0E
			39 00 00 40 00 00 06 F0 55 AA 52 08 00
			39 00 00 40 00 00 02 6F 78
			39 00 00 40 00 00 18 B0 10 00 2A 00 C2 01 DA 03 7C 05 B1 08 80 0B EE 0F FF 05 55 05 56 05 55
			39 00 00 40 00 00 02 6F 6F
			39 00 00 40 00 00 07 B0 02 64 04 C8 02 64
			39 00 00 40 00 00 06 F0 55 AA 52 08 08
			39 00 00 40 00 00 17 C1 8D FF DD FF FF DD FF FF DD FF FF DD FF FF EE FF FF AA 7C 1E 0E FF
			39 00 00 40 00 00 02 6F 23
			39 00 00 40 00 00 15 C1 0D FF DD FF FF DD FF FF DD FF FF DD FF FF EE FF FF AA 7C 1E
			39 00 00 40 00 00 02 6F 37
			39 00 00 40 00 00 15 C1 0D FF DD FF FF DD FF FF DD FF FF DD FF FF EE FF FF FF FF FF
			39 00 00 40 00 00 02 6F 4B
			39 00 00 40 00 00 15 C1 0D FF DD FF FF DD FF FF DD FF FF DD FF FF EE FF FF AA 7C 1E
			39 00 00 40 00 00 02 6F 5F
			39 00 00 40 00 00 15 C1 0D FF DD FF FF DD FF FF DD FF FF DD FF FF EE FF FF FF FF FF
			39 00 00 40 00 00 02 6F 73
			39 00 00 40 00 00 15 C1 0D FF DD FF FF DD FF FF DD FF FF DD FF FF EE FF FF AA 7C 1E
			39 00 00 40 00 00 11 BA 00 04 03 A4 03 A4 05 B8 05 B8 07 D8 07 D8 0A 84
			39 00 00 40 00 00 02 6F 10
			39 00 00 40 00 00 11 BA 0A 84 0D C3 0D C3 0D C4 0D C4 1D 24 1D 24 2C 50
			39 00 00 40 00 00 02 6F 20
			39 00 00 40 00 00 0d BA 2C 50 36 E8 36 E8 3A FE 3A FE 3F FC
			39 00 00 40 00 00 02 6F 20
			39 00 00 40 00 00 04 C1 04 52 CD
			39 00 00 40 00 00 02 6F 1D
			39 00 00 40 00 00 04 C1 00 80 FF
			39 00 00 40 00 00 02 6F 07
			39 00 00 40 00 00 02 51 00
			39 00 00 40 00 00 05 FF AA 55 A5 81
			39 00 00 40 00 00 02 6F 02
			39 00 00 40 00 00 02 F9 04
			39 00 00 40 00 00 05 FF AA 55 A5 81
			39 00 00 40 00 00 02 6F 0D
			39 00 00 40 00 00 02 FB 80
			39 00 00 40 00 00 05 FF AA 55 A5 81
			39 00 00 40 00 00 02 6F 10
			39 00 00 40 00 00 02 FB 40
			39 00 00 40 00 00 05 FF AA 55 A5 81
			39 00 00 40 00 00 02 6F 0C
			39 00 00 40 00 00 02 FD 08
			39 00 00 40 00 00 05 FF AA 55 A5 81
			39 00 00 40 00 00 02 6F 05
			39 00 00 40 00 00 03 FE 3C 3C
			39 00 00 40 00 00 05 FF AA 55 A5 80
			39 00 00 40 00 00 02 6F 0A
			39 00 00 40 00 00 06 F6 70 70 70 70 70
			39 00 00 40 00 00 05 2A 00 00 04 C7
			39 00 00 40 00 00 05 2B 00 00 0B AF
			39 00 00 40 00 00 02 5A 02
			39 00 00 40 00 00 02 2F 30
			39 00 00 40 00 00 03 6D 00 00
			39 00 00 40 00 00 02 6F 06
			39 00 00 40 00 00 02 6D 03
			39 00 00 40 00 00 02 6F 02
			39 00 00 40 00 00 02 8C 10
			39 00 00 40 00 00 02 8C 02
			39 00 00 40 00 00 03 5F 00 00
			39 00 00 40 00 00 02 35 00
			39 00 00 40 00 00 02 6F 04
			39 00 00 40 00 00 02 35 00
			39 00 00 40 00 00 03 51 00 00
			39 00 00 40 00 00 02 6F 04
			39 00 00 40 00 00 03 51 00 00
			39 00 00 40 00 00 02 53 20
			39 00 00 40 00 00 02 90 03
			39 00 00 40 00 00 02 6F 01
			39 00 00 40 00 00 02 90 43
			39 00 00 00 00 00 13 91 AB 28 00 10 C2 00 02 32 01 9C 00 08 06 67 05 9C 10 F0
                	05 00 00 00 78 00 01 11
                	05 00 00 00 00 00 01 29];	/* display on */
		qcom,mdss-dsi-off-command = [
			05 00 00 00 00 00 01 28		/* display_off */
			05 00 00 00 64 00 01 10];	/* enter sleep mode */

		qcom,mdss-dsi-on-command-state = "dsi_lp_mode";
		qcom,mdss-dsi-off-command-state = "dsi_lp_mode";
		qcom,mdss-dsi-timing-switch-command-state =
			"dsi_lp_mode";
		qcom,compression-mode = "dsc";
		/* Why QCOM doesn't use this, even it used 2 encoder
		 * as for that dsi_sw43404_amoled_cmd, for ex */
		/* qcom,mdss-dsc-encoders = <2>; */
		qcom,mdss-dsc-version = <0x11>;
		qcom,mdss-dsc-slice-height = <16>;
		qcom,mdss-dsc-slice-width = <612>;
		qcom,mdss-dsc-slice-per-pkt = <2>;
		qcom,mdss-dsc-bit-per-component = <10>;
		qcom,mdss-dsc-bit-per-pixel = <8>;
		qcom,mdss-dsc-block-prediction-enable;
		qcom,mdss-dsc-novateck-ic;
		qcom,mdss-dsi-pcd-check-enable-command = [
			39 00 00 40 00 00 06 F0 55 AA 52 08 06
			39 00 00 40 00 00 03 B1 35 35
			39 00 00 40 00 00 02 6F 01
			39 00 00 40 00 00 02 B2 37
			39 00 00 40 00 00 03 B7 35 35
			39 00 00 40 00 00 02 6F 01
			39 00 00 40 00 00 02 B8 37
			39 00 00 40 00 00 05 FF AA 55 A5 80
			39 00 00 40 00 00 02 6F 12
			39 00 00 40 00 00 04 F4 01 0C 11
			39 00 00 00 00 00 02 9B 00];

		qcom,mdss-dsi-pcd-check-enable-command-state = "dsi_hs_mode";
		qcom,mdss-dsi-pcd-check-disable-command = [
			39 00 00 40 00 00 06 F0 55 AA 52 08 06
			39 00 00 40 00 00 03 B1 37 37
			39 00 00 40 00 00 02 6F 01
			39 00 00 40 00 00 02 B2 36
			39 00 00 40 00 00 03 B7 37 37
			39 00 00 40 00 00 02 6F 01
			39 00 00 40 00 00 02 B8 36
			39 00 00 40 00 00 05 FF AA 55 A5 80
			39 00 00 40 00 00 02 6F 12
			39 00 00 40 00 00 04 F4 00 00 00
			39 00 00 00 00 00 02 9B 01];
		qcom,mdss-dsi-pcd-check-disable-command-state = "dsi_hs_mode";
		qcom,mdss-dsi-pcd-check-in-enable-command = [
			39 00 00 40 00 00 06 F0 55 AA 52 08 01
			39 00 00 00 00 00 03 D0 00 80
			];
		qcom,mdss-dsi-pcd-check-in-enable-command-state = "dsi_hs_mode";
		qcom,mdss-dsi-pcd-check-in-disable-command = [
			39 00 00 40 00 00 06 F0 55 AA 52 08 01
			39 00 00 00 00 00 03 D0 00 00
			];
		qcom,mdss-dsi-pcd-check-in-disable-command-state = "dsi_hs_mode";
		qcom,mdss-dsi-lp1-command = [
			39 00 00 40 00 00 02 6B 00
			39 00 00 40 00 00 06 F0 55 AA 52 08 00
			39 00 00 40 00 00 02 6F CC
			39 00 00 40 00 00 02 B2 00 //exit MAFR
			39 00 00 40 00 00 02 6F 04
			39 00 00 40 00 00 02 35 00
			39 00 00 40 00 00 02 53 20
			39 00 00 40 00 00 02 5A 02
			39 00 00 40 00 00 02 2F 30
			39 00 00 40 00 00 03 6D 00 00
			39 00 00 40 00 00 02 6F 06
			39 00 00 40 00 00 02 6D 03
			39 00 00 40 00 00 02 6F 02
			39 00 00 40 00 00 02 8C 10
			39 00 00 00 11 00 02 8C 02
		];
		qcom,mdss-dsi-lp1-command-state =
			"dsi_lp_mode";
		qcom,mdss-dsi-lp2-command = [
			39 00 00 40 00 00 02 6B 00
			39 00 00 40 00 00 06 F0 55 AA 52 08 00
			39 00 00 40 00 00 02 6F CC
			39 00 00 40 00 00 02 B2 00 //exit MAFR
			39 00 00 40 00 00 02 6F 04
			39 00 00 40 00 00 02 35 00 //TE = 1
			39 00 00 40 00 00 02 53 20 //DBV Diming Enable
			39 00 00 40 00 00 02 5A 00
			39 00 00 40 00 00 02 6F 06
			39 00 00 40 00 00 02 6D 00
			39 00 00 40 00 00 02 2F 30
			39 00 00 40 00 00 03 6D 04 00
			39 00 00 40 00 00 02 6F 02
			39 00 00 40 00 00 02 8C 10
			39 00 00 00 00 00 02 8C 00
		];
		qcom,mdss-dsi-lp2-command-state =
			"dsi_lp_mode";
		qcom,mdss-dsi-nolp-command = [
			39 00 00 40 00 00 02 6B 00
			39 00 00 40 00 00 06 F0 55 AA 52 08 00
			39 00 00 40 00 00 02 6F CC
			39 00 00 40 00 00 02 B2 00 //exit MAFR
			39 00 00 40 00 00 02 6F 04
			39 00 00 40 00 00 02 35 00
			39 00 00 40 00 00 02 53 20
			39 00 00 40 00 00 02 5A 02
			39 00 00 40 00 00 02 2F 30
			39 00 00 40 00 00 03 6D 00 00
			39 00 00 40 00 00 02 6F 06
			39 00 00 40 00 00 02 6D 03
			39 00 00 40 00 00 02 6F 02
			39 00 00 40 00 00 02 8C 10
			39 00 00 00 11 00 02 8C 02
		];
		qcom,mdss-dsi-nolp-command-state =
			"dsi_lp_mode";
	};

	timing@3{
		qcom,mdss-dsi-cmd-mode;
		qcom,mdss-dsi-panel-framerate = <30>;
		qcom,mdss-dsi-panel-width = <1224>;
		qcom,mdss-dsi-panel-height = <2992>;
		qcom,mdss-dsi-h-front-porch = <25>;
		qcom,mdss-dsi-h-back-porch = <16>;
		qcom,mdss-dsi-h-pulse-width = <16>;
		qcom,mdss-dsi-h-sync-skew = <0>;
		qcom,mdss-dsi-h-sync-pulse = <0>;
		qcom,mdss-dsi-v-back-porch = <2>;
		qcom,mdss-dsi-v-front-porch = <2>;
		qcom,mdss-dsi-v-pulse-width = <2>;
		qcom,mdss-dsi-h-left-border = <0>;
		qcom,mdss-dsi-h-right-border = <0>;
		qcom,mdss-dsi-v-top-border = <0>;
		qcom,mdss-dsi-v-bottom-border = <0>;
	        qcom,mdss-dsi-panel-jitter = <0x20 0xa>;
		qcom,mdss-mdp-transfer-time-us = <7933>;
		qcom,mdss-dsi-timing-switch-command = [
			39 00 00 40 00 00 02 6B 00
			39 00 00 40 00 00 06 F0 55 AA 52 08 00
			39 00 00 40 00 00 02 6F CC
			39 00 00 40 00 00 02 B2 00 //exit MAFR
			39 00 00 40 00 00 02 6F 04
			39 00 00 40 00 00 02 35 03
			39 00 00 40 00 00 02 53 28
			39 00 00 40 00 00 02 5A 00
			39 00 00 40 00 00 02 2F 30
			39 00 00 40 00 00 03 6D 01 00
			39 00 00 40 00 00 02 6F 06
			39 00 00 40 00 00 02 6D 00
			39 00 00 40 00 00 02 6F 02
			39 00 00 40 00 00 02 8C 10
			39 00 00 40 00 00 02 8C 00
			39 00 00 40 00 00 06 F0 55 AA 52 08 00
			39 00 00 40 00 00 02 6F 05
			39 00 00 00 00 00 03 B2 04 04
		];
		qcom,mdss-dsi-on-command = [
			39 00 00 40 00 00 06 F0 55 AA 52 08 00
			39 00 00 40 00 00 02 6F 04
			39 00 00 40 00 00 05 C6 33 A3 33 33
			39 00 00 40 00 00 06 F0 55 AA 52 08 01
			39 00 00 40 00 00 02 6F 2F
			39 00 00 40 00 00 02 C3 44
			39 00 00 40 00 00 02 6F 00
			39 00 00 40 00 00 02 C3 DD
			39 00 00 40 00 00 02 6F 04
			39 00 00 40 00 00 02 C3 07
			39 00 00 40 00 00 02 6F 09
			39 00 00 40 00 00 02 C3 07
			39 00 00 40 00 00 06 F0 55 AA 52 08 00
			39 00 00 40 00 00 02 6F 04
			39 00 00 40 00 00 02 B1 07
			39 00 00 40 00 00 02 68 20
			39 00 00 40 00 00 06 F0 55 AA 52 08 09
			39 00 00 40 00 00 02 BD 05
			39 00 00 40 00 00 02 6F 10
			39 00 00 40 00 00 02 C1 00
			39 00 00 40 00 00 02 6F 11
			39 00 00 40 00 00 03 C1 00 0A
			39 00 00 40 00 00 02 6F 13
			39 00 00 40 00 00 03 C1 00 00
			39 00 00 40 00 00 02 6F 00
			39 00 00 40 00 00 06 C6 8A 8D 8D 90 90
			39 00 00 40 00 00 02 6F 05
			39 00 00 40 00 00 06 C6 89 85 83 8A 8A
			39 00 00 40 00 00 02 6F 0A
			39 00 00 40 00 00 06 C6 8A 83 89 84 8A
			39 00 00 40 00 00 02 6F 0F
			39 00 00 40 00 00 06 C6 85 83 83 84 85
			39 00 00 40 00 00 02 6F 14
			39 00 00 40 00 00 06 C6 84 84 85 84 83
			39 00 00 40 00 00 02 6F 19
			39 00 00 40 00 00 06 C6 83 84 83 84 83
			39 00 00 40 00 00 02 6F 1E
			39 00 00 40 00 00 06 C6 8A 8D 8D 90 90
			39 00 00 40 00 00 02 6F 23
			39 00 00 40 00 00 06 C6 89 85 83 8A 8A
			39 00 00 40 00 00 02 6F 28
			39 00 00 40 00 00 06 C6 8A 83 89 84 8A
			39 00 00 40 00 00 02 6F 2D
			39 00 00 40 00 00 06 C6 85 83 83 84 85
			39 00 00 40 00 00 02 6F 32
			39 00 00 40 00 00 06 C6 84 84 85 84 83
			39 00 00 40 00 00 02 6F 37
			39 00 00 40 00 00 06 C6 83 84 83 84 83
			39 00 00 40 00 00 02 6F 3C
			39 00 00 40 00 00 06 C6 8A 8D 8D 90 90
			39 00 00 40 00 00 02 6F 41
			39 00 00 40 00 00 06 C6 89 85 83 8A 8A
			39 00 00 40 00 00 02 6F 46
			39 00 00 40 00 00 06 C6 85 83 89 84 8A
			39 00 00 40 00 00 02 6F 4B
			39 00 00 40 00 00 06 C6 8A 83 83 84 85
			39 00 00 40 00 00 02 6F 50
			39 00 00 40 00 00 06 C6 84 84 85 84 83
			39 00 00 40 00 00 02 6F 55
			39 00 00 40 00 00 06 C6 83 84 83 84 83
			39 00 00 40 00 00 06 F0 55 AA 52 08 00
			39 00 00 40 00 00 02 6F 0D
			39 00 00 40 00 00 02 C2 1A
			39 00 00 40 00 00 06 F0 55 AA 52 08 04
			39 00 00 40 00 00 02 B1 00
			39 00 00 40 00 00 02 6F 0A
			39 00 00 40 00 00 02 B1 20
			39 00 00 40 00 00 02 6F 07
			39 00 00 40 00 00 04 B1 00 00 00
			39 00 00 40 00 00 02 6F 0B
			39 00 00 40 00 00 02 B1 00
			39 00 00 40 00 00 02 6F 06
			39 00 00 40 00 00 02 8D 05
			39 00 00 40 00 00 02 6F 01
			39 00 00 40 00 00 02 8D 20
			39 00 00 40 00 00 02 5A 01
			39 00 00 40 00 00 06 F0 55 AA 52 08 00
			39 00 00 40 00 00 02 6F 31
			39 00 00 40 00 00 04 C0 00 23 00
			39 00 00 40 00 00 02 6F 35
			39 00 00 40 00 00 04 C0 44 41 44
			39 00 00 40 00 00 06 F0 55 AA 52 08 04
			39 00 00 40 00 00 02 C0 20
			39 00 00 40 00 00 05 FF AA 55 A5 80
			39 00 00 40 00 00 02 6F 07
			39 00 00 40 00 00 02 F8 4D
			39 00 00 40 00 00 02 6F 23
			39 00 00 40 00 00 02 F8 4D
			39 00 00 40 00 00 05 FF AA 55 A5 81
			39 00 00 40 00 00 02 6F 21
			39 00 00 40 00 00 02 F5 03
			39 00 00 40 00 00 02 6F 43
			39 00 00 40 00 00 19 F5 01 02 01 04 00 01 02 00 00 00 43 02 00 00 10 00 00 10 05 00 11 31 12 11
			39 00 00 40 00 00 02 6F 1D
			39 00 00 40 00 00 04 FB 64 07 80
			39 00 00 40 00 00 02 6F 07
			39 00 00 40 00 00 02 FC 04
			39 00 00 40 00 00 02 6F 30
			39 00 00 40 00 00 02 FE 20
			39 00 00 40 00 00 05 FF AA 55 A5 84
			39 00 00 40 00 00 02 6F 9A
			39 00 00 40 00 00 02 F3 0F
			39 00 00 40 00 00 02 6F 9F
			39 00 00 40 00 00 02 F4 00
			39 00 00 40 00 00 02 6F E9
			39 00 00 40 00 00 02 F4 03
			39 00 00 40 00 00 02 6F 28
			39 00 00 40 00 00 02 F8 00
			39 00 00 40 00 00 05 FF AA 55 A5 81
			39 00 00 40 00 00 02 6F 0F
			39 00 00 40 00 00 02 F5 0E
			39 00 00 40 00 00 06 F0 55 AA 52 08 00
			39 00 00 40 00 00 02 6F 78
			39 00 00 40 00 00 18 B0 10 00 2A 00 C2 01 DA 03 7C 05 B1 08 80 0B EE 0F FF 05 55 05 56 05 55
			39 00 00 40 00 00 02 6F 6F
			39 00 00 40 00 00 07 B0 02 64 04 C8 02 64
			39 00 00 40 00 00 06 F0 55 AA 52 08 08
			39 00 00 40 00 00 17 C1 8D FF DD FF FF DD FF FF DD FF FF DD FF FF EE FF FF AA 7C 1E 0E FF
			39 00 00 40 00 00 02 6F 23
			39 00 00 40 00 00 15 C1 0D FF DD FF FF DD FF FF DD FF FF DD FF FF EE FF FF AA 7C 1E
			39 00 00 40 00 00 02 6F 37
			39 00 00 40 00 00 15 C1 0D FF DD FF FF DD FF FF DD FF FF DD FF FF EE FF FF FF FF FF
			39 00 00 40 00 00 02 6F 4B
			39 00 00 40 00 00 15 C1 0D FF DD FF FF DD FF FF DD FF FF DD FF FF EE FF FF AA 7C 1E
			39 00 00 40 00 00 02 6F 5F
			39 00 00 40 00 00 15 C1 0D FF DD FF FF DD FF FF DD FF FF DD FF FF EE FF FF FF FF FF
			39 00 00 40 00 00 02 6F 73
			39 00 00 40 00 00 15 C1 0D FF DD FF FF DD FF FF DD FF FF DD FF FF EE FF FF AA 7C 1E
			39 00 00 40 00 00 11 BA 00 04 03 A4 03 A4 05 B8 05 B8 07 D8 07 D8 0A 84
			39 00 00 40 00 00 02 6F 10
			39 00 00 40 00 00 11 BA 0A 84 0D C3 0D C3 0D C4 0D C4 1D 24 1D 24 2C 50
			39 00 00 40 00 00 02 6F 20
			39 00 00 40 00 00 0d BA 2C 50 36 E8 36 E8 3A FE 3A FE 3F FC
			39 00 00 40 00 00 02 6F 20
			39 00 00 40 00 00 04 C1 04 52 CD
			39 00 00 40 00 00 02 6F 1D
			39 00 00 40 00 00 04 C1 00 80 FF
			39 00 00 40 00 00 02 6F 07
			39 00 00 40 00 00 02 51 00
			39 00 00 40 00 00 05 FF AA 55 A5 81
			39 00 00 40 00 00 02 6F 02
			39 00 00 40 00 00 02 F9 04
			39 00 00 40 00 00 05 FF AA 55 A5 81
			39 00 00 40 00 00 02 6F 0D
			39 00 00 40 00 00 02 FB 80
			39 00 00 40 00 00 05 FF AA 55 A5 81
			39 00 00 40 00 00 02 6F 10
			39 00 00 40 00 00 02 FB 40
			39 00 00 40 00 00 05 FF AA 55 A5 81
			39 00 00 40 00 00 02 6F 0C
			39 00 00 40 00 00 02 FD 08
			39 00 00 40 00 00 05 FF AA 55 A5 81
			39 00 00 40 00 00 02 6F 05
			39 00 00 40 00 00 03 FE 3C 3C
			39 00 00 40 00 00 05 FF AA 55 A5 80
			39 00 00 40 00 00 02 6F 0A
			39 00 00 40 00 00 06 F6 70 70 70 70 70
			39 00 00 40 00 00 05 2A 00 00 04 C7
			39 00 00 40 00 00 05 2B 00 00 0B AF
			39 00 00 40 00 00 02 5A 00
			39 00 00 40 00 00 02 2F 30
			39 00 00 40 00 00 03 6D 01 00
			39 00 00 40 00 00 02 6F 06
			39 00 00 40 00 00 02 6D 00
			39 00 00 40 00 00 02 6F 02
			39 00 00 40 00 00 02 8C 10
			39 00 00 40 00 00 02 8C 00
			39 00 00 40 00 00 06 F0 55 AA 52 08 00
			39 00 00 40 00 00 02 6F 05
			39 00 00 40 00 00 03 B2 04 04
			39 00 00 40 00 00 03 5F 00 00
			39 00 00 40 00 00 02 35 00
			39 00 00 40 00 00 02 6F 04
			39 00 00 40 00 00 02 35 03
			39 00 00 40 00 00 03 51 00 00
			39 00 00 40 00 00 02 6F 04
			39 00 00 40 00 00 03 51 00 00
			39 00 00 40 00 00 02 53 28
			39 00 00 40 00 00 02 90 03
			39 00 00 40 00 00 02 6F 01
			39 00 00 40 00 00 02 90 43
			39 00 00 00 00 00 13 91 AB 28 00 10 C2 00 02 32 01 9C 00 08 06 67 05 9C 10 F0
			05 00 00 00 78 00 01 11
			05 00 00 00 00 00 01 29];	/* display on */
		qcom,mdss-dsi-off-command = [
			05 00 00 00 00 00 01 28		/* display_off */
			05 00 00 00 64 00 01 10];	/* enter sleep mode */

		qcom,mdss-dsi-on-command-state = "dsi_lp_mode";
		qcom,mdss-dsi-off-command-state = "dsi_lp_mode";
		qcom,mdss-dsi-timing-switch-command-state =
			"dsi_lp_mode";
		qcom,compression-mode = "dsc";
		/* Why QCOM doesn't use this, even it used 2 encoder
		 * as for that dsi_sw43404_amoled_cmd, for ex */
		/* qcom,mdss-dsc-encoders = <2>; */
		qcom,mdss-dsc-version = <0x11>;
		qcom,mdss-dsc-slice-height = <16>;
		qcom,mdss-dsc-slice-width = <612>;
		qcom,mdss-dsc-slice-per-pkt = <2>;
		qcom,mdss-dsc-bit-per-component = <10>;
		qcom,mdss-dsc-bit-per-pixel = <8>;
		qcom,mdss-dsc-block-prediction-enable;
		qcom,mdss-dsc-novateck-ic;
		qcom,mdss-dsi-pcd-check-in-enable-command = [
			39 00 00 40 00 00 06 F0 55 AA 52 08 01
			39 00 00 00 00 00 03 D0 00 80
			];
		qcom,mdss-dsi-pcd-check-in-enable-command-state = "dsi_hs_mode";
		qcom,mdss-dsi-pcd-check-in-disable-command = [
			39 00 00 40 00 00 06 F0 55 AA 52 08 01
			39 00 00 00 00 00 03 D0 00 00
			];
		qcom,mdss-dsi-pcd-check-in-disable-command-state = "dsi_hs_mode";
		qcom,mdss-dsi-lp1-command = [
			39 00 00 40 00 00 02 6B 00
			39 00 00 40 00 00 06 F0 55 AA 52 08 00
			39 00 00 40 00 00 02 6F CC
			39 00 00 40 00 00 02 B2 00 //exit MAFR
			39 00 00 40 00 00 02 6F 04
			39 00 00 40 00 00 02 35 03
			39 00 00 40 00 00 02 53 28
			39 00 00 40 00 00 02 5A 00
			39 00 00 40 00 00 02 2F 30
			39 00 00 40 00 00 03 6D 01 00
			39 00 00 40 00 00 02 6F 06
			39 00 00 40 00 00 02 6D 00
			39 00 00 40 00 00 02 6F 02
			39 00 00 40 00 00 02 8C 10
			39 00 00 40 00 00 02 8C 00
			39 00 00 40 00 00 06 F0 55 AA 52 08 00
			39 00 00 40 00 00 02 6F 05
			39 00 00 00 00 00 03 B2 04 04
		];
		qcom,mdss-dsi-lp1-command-state =
			"dsi_lp_mode";
		qcom,mdss-dsi-lp2-command = [
			39 00 00 40 00 00 02 6B 00
			39 00 00 40 00 00 06 F0 55 AA 52 08 00
			39 00 00 40 00 00 02 6F CC
			39 00 00 40 00 00 02 B2 00 //exit MAFR
			39 00 00 40 00 00 02 6F 04
			39 00 00 40 00 00 02 35 00 //TE = 1
			39 00 00 40 00 00 02 53 20 //DBV Diming Enable
			39 00 00 40 00 00 02 5A 00
			39 00 00 40 00 00 02 6F 06
			39 00 00 40 00 00 02 6D 00
			39 00 00 40 00 00 02 2F 30
			39 00 00 40 00 00 03 6D 04 00
			39 00 00 40 00 00 02 6F 02
			39 00 00 40 00 00 02 8C 10
			39 00 00 00 00 00 02 8C 00
		];
		qcom,mdss-dsi-lp2-command-state =
			"dsi_lp_mode";
		qcom,mdss-dsi-nolp-command = [
			39 00 00 40 00 00 02 6B 00
			39 00 00 40 00 00 06 F0 55 AA 52 08 00
			39 00 00 40 00 00 02 6F CC
			39 00 00 40 00 00 02 B2 00 //exit MAFR
			39 00 00 40 00 00 02 6F 04
			39 00 00 40 00 00 02 35 03
			39 00 00 40 00 00 02 53 28
			39 00 00 40 00 00 02 5A 00
			39 00 00 40 00 00 02 2F 30
			39 00 00 40 00 00 03 6D 01 00
			39 00 00 40 00 00 02 6F 06
			39 00 00 40 00 00 02 6D 00
			39 00 00 40 00 00 02 6F 02
			39 00 00 40 00 00 02 8C 10
			39 00 00 40 00 00 02 8C 00
			39 00 00 40 00 00 06 F0 55 AA 52 08 00
			39 00 00 40 00 00 02 6F 05
			39 00 00 00 00 00 03 B2 04 04
		];
		qcom,mdss-dsi-nolp-command-state =
			"dsi_lp_mode";
	};

	timing@4{
		qcom,mdss-dsi-cmd-mode;
		qcom,mdss-dsi-panel-framerate = <24>;
		qcom,mdss-dsi-panel-width = <1224>;
		qcom,mdss-dsi-panel-height = <2992>;
		qcom,mdss-dsi-h-front-porch = <25>;
		qcom,mdss-dsi-h-back-porch = <16>;
		qcom,mdss-dsi-h-pulse-width = <16>;
		qcom,mdss-dsi-h-sync-skew = <0>;
		qcom,mdss-dsi-h-sync-pulse = <0>;
		qcom,mdss-dsi-v-back-porch = <2>;
		qcom,mdss-dsi-v-front-porch = <2>;
		qcom,mdss-dsi-v-pulse-width = <2>;
		qcom,mdss-dsi-h-left-border = <0>;
		qcom,mdss-dsi-h-right-border = <0>;
		qcom,mdss-dsi-v-top-border = <0>;
		qcom,mdss-dsi-v-bottom-border = <0>;
	        qcom,mdss-dsi-panel-jitter = <0x20 0xa>;
		qcom,mdss-mdp-transfer-time-us = <7933>;
		qcom,mdss-dsi-timing-switch-command = [
			39 00 00 40 00 00 02 6B 00
			39 00 00 40 00 00 06 F0 55 AA 52 08 00
			39 00 00 40 00 00 02 6F CC
			39 00 00 40 00 00 02 B2 00 //exit MAFR
			39 00 00 40 00 00 02 6F 04
			39 00 00 40 00 00 02 35 04
			39 00 00 40 00 00 02 53 28
			39 00 00 40 00 00 02 5A 00
			39 00 00 40 00 00 02 2F 30
			39 00 00 40 00 00 03 6D 02 00
			39 00 00 40 00 00 02 6F 06
			39 00 00 40 00 00 02 6D 00
			39 00 00 40 00 00 02 6F 02
			39 00 00 40 00 00 02 8C 10
			39 00 00 40 00 00 02 8C 00
			39 00 00 40 00 00 06 F0 55 AA 52 08 00
			39 00 00 40 00 00 02 6F 05
			39 00 00 00 00 00 03 B2 05 05
		];
		qcom,mdss-dsi-on-command = [
			39 00 00 40 00 00 06 F0 55 AA 52 08 00
			39 00 00 40 00 00 02 6F 04
			39 00 00 40 00 00 05 C6 33 A3 33 33
			39 00 00 40 00 00 06 F0 55 AA 52 08 01
			39 00 00 40 00 00 02 6F 2F
			39 00 00 40 00 00 02 C3 44
			39 00 00 40 00 00 02 6F 00
			39 00 00 40 00 00 02 C3 DD
			39 00 00 40 00 00 02 6F 04
			39 00 00 40 00 00 02 C3 07
			39 00 00 40 00 00 02 6F 09
			39 00 00 40 00 00 02 C3 07
			39 00 00 40 00 00 06 F0 55 AA 52 08 00
			39 00 00 40 00 00 02 6F 04
			39 00 00 40 00 00 02 B1 07
			39 00 00 40 00 00 02 68 20
			39 00 00 40 00 00 06 F0 55 AA 52 08 09
			39 00 00 40 00 00 02 BD 05
			39 00 00 40 00 00 02 6F 10
			39 00 00 40 00 00 02 C1 00
			39 00 00 40 00 00 02 6F 11
			39 00 00 40 00 00 03 C1 00 0A
			39 00 00 40 00 00 02 6F 13
			39 00 00 40 00 00 03 C1 00 00
			39 00 00 40 00 00 02 6F 00
			39 00 00 40 00 00 06 C6 8A 8D 8D 90 90
			39 00 00 40 00 00 02 6F 05
			39 00 00 40 00 00 06 C6 89 85 83 8A 8A
			39 00 00 40 00 00 02 6F 0A
			39 00 00 40 00 00 06 C6 8A 83 89 84 8A
			39 00 00 40 00 00 02 6F 0F
			39 00 00 40 00 00 06 C6 85 83 83 84 85
			39 00 00 40 00 00 02 6F 14
			39 00 00 40 00 00 06 C6 84 84 85 84 83
			39 00 00 40 00 00 02 6F 19
			39 00 00 40 00 00 06 C6 83 84 83 84 83
			39 00 00 40 00 00 02 6F 1E
			39 00 00 40 00 00 06 C6 8A 8D 8D 90 90
			39 00 00 40 00 00 02 6F 23
			39 00 00 40 00 00 06 C6 89 85 83 8A 8A
			39 00 00 40 00 00 02 6F 28
			39 00 00 40 00 00 06 C6 8A 83 89 84 8A
			39 00 00 40 00 00 02 6F 2D
			39 00 00 40 00 00 06 C6 85 83 83 84 85
			39 00 00 40 00 00 02 6F 32
			39 00 00 40 00 00 06 C6 84 84 85 84 83
			39 00 00 40 00 00 02 6F 37
			39 00 00 40 00 00 06 C6 83 84 83 84 83
			39 00 00 40 00 00 02 6F 3C
			39 00 00 40 00 00 06 C6 8A 8D 8D 90 90
			39 00 00 40 00 00 02 6F 41
			39 00 00 40 00 00 06 C6 89 85 83 8A 8A
			39 00 00 40 00 00 02 6F 46
			39 00 00 40 00 00 06 C6 85 83 89 84 8A
			39 00 00 40 00 00 02 6F 4B
			39 00 00 40 00 00 06 C6 8A 83 83 84 85
			39 00 00 40 00 00 02 6F 50
			39 00 00 40 00 00 06 C6 84 84 85 84 83
			39 00 00 40 00 00 02 6F 55
			39 00 00 40 00 00 06 C6 83 84 83 84 83
			39 00 00 40 00 00 06 F0 55 AA 52 08 00
			39 00 00 40 00 00 02 6F 0D
			39 00 00 40 00 00 02 C2 1A
			39 00 00 40 00 00 06 F0 55 AA 52 08 04
			39 00 00 40 00 00 02 B1 00
			39 00 00 40 00 00 02 6F 0A
			39 00 00 40 00 00 02 B1 20
			39 00 00 40 00 00 02 6F 07
			39 00 00 40 00 00 04 B1 00 00 00
			39 00 00 40 00 00 02 6F 0B
			39 00 00 40 00 00 02 B1 00
			39 00 00 40 00 00 02 6F 06
			39 00 00 40 00 00 02 8D 05
			39 00 00 40 00 00 02 6F 01
			39 00 00 40 00 00 02 8D 20
			39 00 00 40 00 00 02 5A 01
			39 00 00 40 00 00 06 F0 55 AA 52 08 00
			39 00 00 40 00 00 02 6F 31
			39 00 00 40 00 00 04 C0 00 23 00
			39 00 00 40 00 00 02 6F 35
			39 00 00 40 00 00 04 C0 44 41 44
			39 00 00 40 00 00 06 F0 55 AA 52 08 04
			39 00 00 40 00 00 02 C0 20
			39 00 00 40 00 00 05 FF AA 55 A5 80
			39 00 00 40 00 00 02 6F 07
			39 00 00 40 00 00 02 F8 4D
			39 00 00 40 00 00 02 6F 23
			39 00 00 40 00 00 02 F8 4D
			39 00 00 40 00 00 05 FF AA 55 A5 81
			39 00 00 40 00 00 02 6F 21
			39 00 00 40 00 00 02 F5 03
			39 00 00 40 00 00 02 6F 43
			39 00 00 40 00 00 19 F5 01 02 01 04 00 01 02 00 00 00 43 02 00 00 10 00 00 10 05 00 11 31 12 11
			39 00 00 40 00 00 02 6F 1D
			39 00 00 40 00 00 04 FB 64 07 80
			39 00 00 40 00 00 02 6F 07
			39 00 00 40 00 00 02 FC 04
			39 00 00 40 00 00 02 6F 30
			39 00 00 40 00 00 02 FE 20
			39 00 00 40 00 00 05 FF AA 55 A5 84
			39 00 00 40 00 00 02 6F 9A
			39 00 00 40 00 00 02 F3 0F
			39 00 00 40 00 00 02 6F 9F
			39 00 00 40 00 00 02 F4 00
			39 00 00 40 00 00 02 6F E9
			39 00 00 40 00 00 02 F4 03
			39 00 00 40 00 00 02 6F 28
			39 00 00 40 00 00 02 F8 00
			39 00 00 40 00 00 05 FF AA 55 A5 81
			39 00 00 40 00 00 02 6F 0F
			39 00 00 40 00 00 02 F5 0E
			39 00 00 40 00 00 06 F0 55 AA 52 08 00
			39 00 00 40 00 00 02 6F 78
			39 00 00 40 00 00 18 B0 10 00 2A 00 C2 01 DA 03 7C 05 B1 08 80 0B EE 0F FF 05 55 05 56 05 55
			39 00 00 40 00 00 02 6F 6F
			39 00 00 40 00 00 07 B0 02 64 04 C8 02 64
			39 00 00 40 00 00 06 F0 55 AA 52 08 08
			39 00 00 40 00 00 17 C1 8D FF DD FF FF DD FF FF DD FF FF DD FF FF EE FF FF AA 7C 1E 0E FF
			39 00 00 40 00 00 02 6F 23
			39 00 00 40 00 00 15 C1 0D FF DD FF FF DD FF FF DD FF FF DD FF FF EE FF FF AA 7C 1E
			39 00 00 40 00 00 02 6F 37
			39 00 00 40 00 00 15 C1 0D FF DD FF FF DD FF FF DD FF FF DD FF FF EE FF FF FF FF FF
			39 00 00 40 00 00 02 6F 4B
			39 00 00 40 00 00 15 C1 0D FF DD FF FF DD FF FF DD FF FF DD FF FF EE FF FF AA 7C 1E
			39 00 00 40 00 00 02 6F 5F
			39 00 00 40 00 00 15 C1 0D FF DD FF FF DD FF FF DD FF FF DD FF FF EE FF FF FF FF FF
			39 00 00 40 00 00 02 6F 73
			39 00 00 40 00 00 15 C1 0D FF DD FF FF DD FF FF DD FF FF DD FF FF EE FF FF AA 7C 1E
			39 00 00 40 00 00 11 BA 00 04 03 A4 03 A4 05 B8 05 B8 07 D8 07 D8 0A 84
			39 00 00 40 00 00 02 6F 10
			39 00 00 40 00 00 11 BA 0A 84 0D C3 0D C3 0D C4 0D C4 1D 24 1D 24 2C 50
			39 00 00 40 00 00 02 6F 20
			39 00 00 40 00 00 0d BA 2C 50 36 E8 36 E8 3A FE 3A FE 3F FC
			39 00 00 40 00 00 02 6F 20
			39 00 00 40 00 00 04 C1 04 52 CD
			39 00 00 40 00 00 02 6F 1D
			39 00 00 40 00 00 04 C1 00 80 FF
			39 00 00 40 00 00 02 6F 07
			39 00 00 40 00 00 02 51 00
			39 00 00 40 00 00 05 FF AA 55 A5 81
			39 00 00 40 00 00 02 6F 02
			39 00 00 40 00 00 02 F9 04
			39 00 00 40 00 00 05 FF AA 55 A5 81
			39 00 00 40 00 00 02 6F 0D
			39 00 00 40 00 00 02 FB 80
			39 00 00 40 00 00 05 FF AA 55 A5 81
			39 00 00 40 00 00 02 6F 10
			39 00 00 40 00 00 02 FB 40
			39 00 00 40 00 00 05 FF AA 55 A5 81
			39 00 00 40 00 00 02 6F 0C
			39 00 00 40 00 00 02 FD 08
			39 00 00 40 00 00 05 FF AA 55 A5 81
			39 00 00 40 00 00 02 6F 05
			39 00 00 40 00 00 03 FE 3C 3C
			39 00 00 40 00 00 05 FF AA 55 A5 80
			39 00 00 40 00 00 02 6F 0A
			39 00 00 40 00 00 06 F6 70 70 70 70 70
			39 00 00 40 00 00 05 2A 00 00 04 C7
			39 00 00 40 00 00 05 2B 00 00 0B AF
			39 00 00 40 00 00 02 5A 00
			39 00 00 40 00 00 02 2F 30
			39 00 00 40 00 00 03 6D 02 00
			39 00 00 40 00 00 02 6F 06
			39 00 00 40 00 00 02 6D 00
			39 00 00 40 00 00 02 6F 02
			39 00 00 40 00 00 02 8C 10
			39 00 00 40 00 00 02 8C 00
			39 00 00 40 00 00 06 F0 55 AA 52 08 00
			39 00 00 40 00 00 02 6F 05
			39 00 00 40 00 00 03 B2 05 05
			39 00 00 40 00 00 03 5F 00 00
			39 00 00 40 00 00 02 35 00
			39 00 00 40 00 00 02 6F 04
			39 00 00 40 00 00 02 35 04
			39 00 00 40 00 00 03 51 00 00
			39 00 00 40 00 00 02 6F 04
			39 00 00 40 00 00 03 51 00 00
			39 00 00 40 00 00 02 53 28
			39 00 00 40 00 00 02 90 03
			39 00 00 40 00 00 02 6F 01
			39 00 00 40 00 00 02 90 43
			39 00 00 00 00 00 13 91 AB 28 00 10 C2 00 02 32 01 9C 00 08 06 67 05 9C 10 F0
                	05 00 00 00 78 00 01 11
                	05 00 00 00 00 00 01 29];	/* display on */
		qcom,mdss-dsi-off-command = [
			05 00 00 00 00 00 01 28		/* display_off */
			05 00 00 00 64 00 01 10];	/* enter sleep mode */

		qcom,mdss-dsi-on-command-state = "dsi_lp_mode";
		qcom,mdss-dsi-off-command-state = "dsi_lp_mode";
		qcom,mdss-dsi-timing-switch-command-state =
			"dsi_lp_mode";
		qcom,compression-mode = "dsc";
		/* Why QCOM doesn't use this, even it used 2 encoder
		 * as for that dsi_sw43404_amoled_cmd, for ex */
		/* qcom,mdss-dsc-encoders = <2>; */
		qcom,mdss-dsc-version = <0x11>;
		qcom,mdss-dsc-slice-height = <16>;
		qcom,mdss-dsc-slice-width = <612>;
		qcom,mdss-dsc-slice-per-pkt = <2>;
		qcom,mdss-dsc-bit-per-component = <10>;
		qcom,mdss-dsc-bit-per-pixel = <8>;
		qcom,mdss-dsc-block-prediction-enable;
		qcom,mdss-dsc-novateck-ic;
		qcom,mdss-dsi-pcd-check-in-enable-command = [
			39 00 00 40 00 00 06 F0 55 AA 52 08 01
			39 00 00 00 00 00 03 D0 00 80
			];
		qcom,mdss-dsi-pcd-check-in-enable-command-state = "dsi_hs_mode";
		qcom,mdss-dsi-pcd-check-in-disable-command = [
			39 00 00 40 00 00 06 F0 55 AA 52 08 01
			39 00 00 00 00 00 03 D0 00 00
			];
		qcom,mdss-dsi-pcd-check-in-disable-command-state = "dsi_hs_mode";
		qcom,mdss-dsi-lp1-command = [
			39 00 00 40 00 00 02 6B 00
			39 00 00 40 00 00 06 F0 55 AA 52 08 00
			39 00 00 40 00 00 02 6F CC
			39 00 00 40 00 00 02 B2 00 //exit MAFR
			39 00 00 40 00 00 02 6F 04
			39 00 00 40 00 00 02 35 04
			39 00 00 40 00 00 02 53 28
			39 00 00 40 00 00 02 5A 00
			39 00 00 40 00 00 02 2F 30
			39 00 00 40 00 00 03 6D 02 00
			39 00 00 40 00 00 02 6F 06
			39 00 00 40 00 00 02 6D 00
			39 00 00 40 00 00 02 6F 02
			39 00 00 40 00 00 02 8C 10
			39 00 00 40 00 00 02 8C 00
			39 00 00 40 00 00 06 F0 55 AA 52 08 00
			39 00 00 40 00 00 02 6F 05
			39 00 00 00 00 00 03 B2 05 05
		];
		qcom,mdss-dsi-lp1-command-state =
			"dsi_lp_mode";
		qcom,mdss-dsi-lp2-command = [
			39 00 00 40 00 00 02 6B 00
			39 00 00 40 00 00 06 F0 55 AA 52 08 00
			39 00 00 40 00 00 02 6F CC
			39 00 00 40 00 00 02 B2 00 //exit MAFR
			39 00 00 40 00 00 02 6F 04
			39 00 00 40 00 00 02 35 00 //TE = 1
			39 00 00 40 00 00 02 53 20 //DBV Diming Enable
			39 00 00 40 00 00 02 5A 00
			39 00 00 40 00 00 02 6F 06
			39 00 00 40 00 00 02 6D 00
			39 00 00 40 00 00 02 2F 30
			39 00 00 40 00 00 03 6D 04 00
			39 00 00 40 00 00 02 6F 02
			39 00 00 40 00 00 02 8C 10
			39 00 00 00 00 00 02 8C 00
		];
		qcom,mdss-dsi-lp2-command-state =
			"dsi_lp_mode";
		qcom,mdss-dsi-nolp-command = [
			39 00 00 40 00 00 02 6B 00
			39 00 00 40 00 00 06 F0 55 AA 52 08 00
			39 00 00 40 00 00 02 6F CC
			39 00 00 40 00 00 02 B2 00 //exit MAFR
			39 00 00 40 00 00 02 6F 04
			39 00 00 40 00 00 02 35 04
			39 00 00 40 00 00 02 53 28
			39 00 00 40 00 00 02 5A 00
			39 00 00 40 00 00 02 2F 30
			39 00 00 40 00 00 03 6D 02 00
			39 00 00 40 00 00 02 6F 06
			39 00 00 40 00 00 02 6D 00
			39 00 00 40 00 00 02 6F 02
			39 00 00 40 00 00 02 8C 10
			39 00 00 40 00 00 02 8C 00
			39 00 00 40 00 00 06 F0 55 AA 52 08 00
			39 00 00 40 00 00 02 6F 05
			39 00 00 00 00 00 03 B2 05 05
		];
		qcom,mdss-dsi-nolp-command-state =
			"dsi_lp_mode";
	};

	timing@5{
		qcom,mdss-dsi-cmd-mode;
		qcom,mdss-dsi-panel-framerate = <120>;  /* Actually 10 hz*/
		qcom,mdss-dsi-panel-width = <1224>;
		qcom,mdss-dsi-panel-height = <2992>;
		qcom,mdss-dsi-h-front-porch = <29>;
		qcom,mdss-dsi-h-back-porch = <16>;
		qcom,mdss-dsi-h-pulse-width = <16>;
		qcom,mdss-dsi-h-sync-skew = <0>;
		qcom,mdss-dsi-h-sync-pulse = <0>;
		qcom,mdss-dsi-v-back-porch = <2>;
		qcom,mdss-dsi-v-front-porch = <2>;
		qcom,mdss-dsi-v-pulse-width = <2>;
		qcom,mdss-dsi-h-left-border = <0>;
		qcom,mdss-dsi-h-right-border = <0>;
		qcom,mdss-dsi-v-top-border = <0>;
		qcom,mdss-dsi-v-bottom-border = <0>;
	        qcom,mdss-dsi-panel-jitter = <0x20 0xa>;
		qcom,mdss-mdp-transfer-time-us = <7933>;
		qcom,mdss-dsi-timing-switch-command = [
			39 00 00 40 00 00 02 6B 00
			39 00 00 40 00 00 06 F0 55 AA 52 08 00
			39 00 00 40 00 00 02 6F CC
			39 00 00 40 00 00 02 B2 00 //exit MAFR
			39 00 00 40 00 00 02 6F 04
			39 00 00 40 00 00 02 35 00 //TE = 1
			39 00 00 40 00 00 02 53 20 //DBV Diming Enable
			39 00 00 40 00 00 02 5A 00
			39 00 00 40 00 00 02 6F 06
			39 00 00 40 00 00 02 6D 00
			39 00 00 40 00 00 02 2F 30
			39 00 00 40 00 00 03 6D 03 00
			39 00 00 40 00 00 02 6F 02
			39 00 00 40 00 00 02 8C 10
			39 00 00 00 00 00 02 8C 00
		];
		qcom,mdss-dsi-on-command = [
			39 00 00 40 00 00 06 F0 55 AA 52 08 00
			39 00 00 40 00 00 02 6F 04
			39 00 00 40 00 00 05 C6 33 A3 33 33
			39 00 00 40 00 00 06 F0 55 AA 52 08 01
			39 00 00 40 00 00 02 6F 2F
			39 00 00 40 00 00 02 C3 44
			39 00 00 40 00 00 02 6F 00
			39 00 00 40 00 00 02 C3 DD
			39 00 00 40 00 00 02 6F 04
			39 00 00 40 00 00 02 C3 07
			39 00 00 40 00 00 02 6F 09
			39 00 00 40 00 00 02 C3 07
			39 00 00 40 00 00 06 F0 55 AA 52 08 00
			39 00 00 40 00 00 02 6F 04
			39 00 00 40 00 00 02 B1 07
			39 00 00 40 00 00 02 68 20
			39 00 00 40 00 00 06 F0 55 AA 52 08 09
			39 00 00 40 00 00 02 BD 05
			39 00 00 40 00 00 02 6F 10
			39 00 00 40 00 00 02 C1 00
			39 00 00 40 00 00 02 6F 11
			39 00 00 40 00 00 03 C1 00 0A
			39 00 00 40 00 00 02 6F 13
			39 00 00 40 00 00 03 C1 00 00
			39 00 00 40 00 00 02 6F 00
			39 00 00 40 00 00 06 C6 8A 8D 8D 90 90
			39 00 00 40 00 00 02 6F 05
			39 00 00 40 00 00 06 C6 89 85 83 8A 8A
			39 00 00 40 00 00 02 6F 0A
			39 00 00 40 00 00 06 C6 8A 83 89 84 8A
			39 00 00 40 00 00 02 6F 0F
			39 00 00 40 00 00 06 C6 85 83 83 84 85
			39 00 00 40 00 00 02 6F 14
			39 00 00 40 00 00 06 C6 84 84 85 84 83
			39 00 00 40 00 00 02 6F 19
			39 00 00 40 00 00 06 C6 83 84 83 84 83
			39 00 00 40 00 00 02 6F 1E
			39 00 00 40 00 00 06 C6 8A 8D 8D 90 90
			39 00 00 40 00 00 02 6F 23
			39 00 00 40 00 00 06 C6 89 85 83 8A 8A
			39 00 00 40 00 00 02 6F 28
			39 00 00 40 00 00 06 C6 8A 83 89 84 8A
			39 00 00 40 00 00 02 6F 2D
			39 00 00 40 00 00 06 C6 85 83 83 84 85
			39 00 00 40 00 00 02 6F 32
			39 00 00 40 00 00 06 C6 84 84 85 84 83
			39 00 00 40 00 00 02 6F 37
			39 00 00 40 00 00 06 C6 83 84 83 84 83
			39 00 00 40 00 00 02 6F 3C
			39 00 00 40 00 00 06 C6 8A 8D 8D 90 90
			39 00 00 40 00 00 02 6F 41
			39 00 00 40 00 00 06 C6 89 85 83 8A 8A
			39 00 00 40 00 00 02 6F 46
			39 00 00 40 00 00 06 C6 85 83 89 84 8A
			39 00 00 40 00 00 02 6F 4B
			39 00 00 40 00 00 06 C6 8A 83 83 84 85
			39 00 00 40 00 00 02 6F 50
			39 00 00 40 00 00 06 C6 84 84 85 84 83
			39 00 00 40 00 00 02 6F 55
			39 00 00 40 00 00 06 C6 83 84 83 84 83
			39 00 00 40 00 00 06 F0 55 AA 52 08 00
			39 00 00 40 00 00 02 6F 0D
			39 00 00 40 00 00 02 C2 1A
			39 00 00 40 00 00 06 F0 55 AA 52 08 04
			39 00 00 40 00 00 02 B1 00
			39 00 00 40 00 00 02 6F 0A
			39 00 00 40 00 00 02 B1 20
			39 00 00 40 00 00 02 6F 07
			39 00 00 40 00 00 04 B1 00 00 00
			39 00 00 40 00 00 02 6F 0B
			39 00 00 40 00 00 02 B1 00
			39 00 00 40 00 00 02 6F 06
			39 00 00 40 00 00 02 8D 05
			39 00 00 40 00 00 02 6F 01
			39 00 00 40 00 00 02 8D 20
			39 00 00 40 00 00 02 5A 01
			39 00 00 40 00 00 06 F0 55 AA 52 08 00
			39 00 00 40 00 00 02 6F 31
			39 00 00 40 00 00 04 C0 00 23 00
			39 00 00 40 00 00 02 6F 35
			39 00 00 40 00 00 04 C0 44 41 44
			39 00 00 40 00 00 06 F0 55 AA 52 08 04
			39 00 00 40 00 00 02 C0 20
			39 00 00 40 00 00 05 FF AA 55 A5 80
			39 00 00 40 00 00 02 6F 07
			39 00 00 40 00 00 02 F8 4D
			39 00 00 40 00 00 02 6F 23
			39 00 00 40 00 00 02 F8 4D
			39 00 00 40 00 00 05 FF AA 55 A5 81
			39 00 00 40 00 00 02 6F 21
			39 00 00 40 00 00 02 F5 03
			39 00 00 40 00 00 02 6F 43
			39 00 00 40 00 00 19 F5 01 02 01 04 00 01 02 00 00 00 43 02 00 00 10 00 00 10 05 00 11 31 12 11
			39 00 00 40 00 00 02 6F 1D
			39 00 00 40 00 00 04 FB 64 07 80
			39 00 00 40 00 00 02 6F 07
			39 00 00 40 00 00 02 FC 04
			39 00 00 40 00 00 02 6F 30
			39 00 00 40 00 00 02 FE 20
			39 00 00 40 00 00 05 FF AA 55 A5 84
			39 00 00 40 00 00 02 6F 9A
			39 00 00 40 00 00 02 F3 0F
			39 00 00 40 00 00 02 6F 9F
			39 00 00 40 00 00 02 F4 00
			39 00 00 40 00 00 02 6F E9
			39 00 00 40 00 00 02 F4 03
			39 00 00 40 00 00 02 6F 28
			39 00 00 40 00 00 02 F8 00
			39 00 00 40 00 00 05 FF AA 55 A5 81
			39 00 00 40 00 00 02 6F 0F
			39 00 00 40 00 00 02 F5 0E
			39 00 00 40 00 00 06 F0 55 AA 52 08 00
			39 00 00 40 00 00 02 6F 78
			39 00 00 40 00 00 18 B0 10 00 2A 00 C2 01 DA 03 7C 05 B1 08 80 0B EE 0F FF 05 55 05 56 05 55
			39 00 00 40 00 00 02 6F 6F
			39 00 00 40 00 00 07 B0 02 64 04 C8 02 64
			39 00 00 40 00 00 06 F0 55 AA 52 08 08
			39 00 00 40 00 00 17 C1 8D FF DD FF FF DD FF FF DD FF FF DD FF FF EE FF FF AA 7C 1E 0E FF
			39 00 00 40 00 00 02 6F 23
			39 00 00 40 00 00 15 C1 0D FF DD FF FF DD FF FF DD FF FF DD FF FF EE FF FF AA 7C 1E
			39 00 00 40 00 00 02 6F 37
			39 00 00 40 00 00 15 C1 0D FF DD FF FF DD FF FF DD FF FF DD FF FF EE FF FF FF FF FF
			39 00 00 40 00 00 02 6F 4B
			39 00 00 40 00 00 15 C1 0D FF DD FF FF DD FF FF DD FF FF DD FF FF EE FF FF AA 7C 1E
			39 00 00 40 00 00 02 6F 5F
			39 00 00 40 00 00 15 C1 0D FF DD FF FF DD FF FF DD FF FF DD FF FF EE FF FF FF FF FF
			39 00 00 40 00 00 02 6F 73
			39 00 00 40 00 00 15 C1 0D FF DD FF FF DD FF FF DD FF FF DD FF FF EE FF FF AA 7C 1E
			39 00 00 40 00 00 11 BA 00 04 03 A4 03 A4 05 B8 05 B8 07 D8 07 D8 0A 84
			39 00 00 40 00 00 02 6F 10
			39 00 00 40 00 00 11 BA 0A 84 0D C3 0D C3 0D C4 0D C4 1D 24 1D 24 2C 50
			39 00 00 40 00 00 02 6F 20
			39 00 00 40 00 00 0d BA 2C 50 36 E8 36 E8 3A FE 3A FE 3F FC
			39 00 00 40 00 00 02 6F 20
			39 00 00 40 00 00 04 C1 04 52 CD
			39 00 00 40 00 00 02 6F 1D
			39 00 00 40 00 00 04 C1 00 80 FF
			39 00 00 40 00 00 02 6F 07
			39 00 00 40 00 00 02 51 00
			39 00 00 40 00 00 05 FF AA 55 A5 81
			39 00 00 40 00 00 02 6F 02
			39 00 00 40 00 00 02 F9 04
			39 00 00 40 00 00 05 FF AA 55 A5 81
			39 00 00 40 00 00 02 6F 0D
			39 00 00 40 00 00 02 FB 80
			39 00 00 40 00 00 05 FF AA 55 A5 81
			39 00 00 40 00 00 02 6F 10
			39 00 00 40 00 00 02 FB 40
			39 00 00 40 00 00 05 FF AA 55 A5 81
			39 00 00 40 00 00 02 6F 0C
			39 00 00 40 00 00 02 FD 08
			39 00 00 40 00 00 05 FF AA 55 A5 81
			39 00 00 40 00 00 02 6F 05
			39 00 00 40 00 00 03 FE 3C 3C
			39 00 00 40 00 00 05 FF AA 55 A5 80
			39 00 00 40 00 00 02 6F 0A
			39 00 00 40 00 00 06 F6 70 70 70 70 70
			39 00 00 40 00 00 05 2A 00 00 04 C7
			39 00 00 40 00 00 05 2B 00 00 0B AF
			39 00 00 40 00 00 02 5A 00
			39 00 00 40 00 00 02 6F 06
			39 00 00 40 00 00 02 6D 00
			39 00 00 40 00 00 02 2F 30
			39 00 00 40 00 00 03 6D 03 00
			39 00 00 40 00 00 02 6F 02
			39 00 00 40 00 00 02 8C 10
			39 00 00 40 00 00 02 8C 00
			39 00 00 40 00 00 03 5F 00 00
			39 00 00 40 00 00 02 35 00
			39 00 00 40 00 00 02 6F 04
			39 00 00 40 00 00 02 35 00
			39 00 00 40 00 00 03 51 00 00
			39 00 00 40 00 00 02 6F 04
			39 00 00 40 00 00 03 51 00 00
			39 00 00 40 00 00 02 53 20
			39 00 00 40 00 00 02 90 03
			39 00 00 40 00 00 02 6F 01
			39 00 00 40 00 00 02 90 43
			39 00 00 00 00 00 13 91 AB 28 00 10 C2 00 02 32 01 9C 00 08 06 67 05 9C 10 F0
                	05 00 00 00 78 00 01 11
                	05 00 00 00 00 00 01 29];	/* display on */
		qcom,mdss-dsi-off-command = [
			05 00 00 00 00 00 01 28		/* display_off */
			05 00 00 00 64 00 01 10];	/* enter sleep mode */

		qcom,mdss-dsi-on-command-state = "dsi_lp_mode";
		qcom,mdss-dsi-off-command-state = "dsi_lp_mode";
		qcom,mdss-dsi-timing-switch-command-state =
			"dsi_lp_mode";
		qcom,compression-mode = "dsc";
		/* Why QCOM doesn't use this, even it used 2 encoder
		 * as for that dsi_sw43404_amoled_cmd, for ex */
		/* qcom,mdss-dsc-encoders = <2>; */
		qcom,mdss-dsc-version = <0x11>;
		qcom,mdss-dsc-slice-height = <16>;
		qcom,mdss-dsc-slice-width = <612>;
		qcom,mdss-dsc-slice-per-pkt = <2>;
		qcom,mdss-dsc-bit-per-component = <10>;
		qcom,mdss-dsc-bit-per-pixel = <8>;
		qcom,mdss-dsc-block-prediction-enable;
		qcom,mdss-dsc-novateck-ic;
		qcom,mdss-dsi-pcd-check-in-enable-command = [
			39 00 00 40 00 00 06 F0 55 AA 52 08 01
			39 00 00 00 00 00 03 D0 00 80
			];
		qcom,mdss-dsi-pcd-check-in-enable-command-state = "dsi_hs_mode";
		qcom,mdss-dsi-pcd-check-in-disable-command = [
			39 00 00 40 00 00 06 F0 55 AA 52 08 01
			39 00 00 00 00 00 03 D0 00 00
			];
		qcom,mdss-dsi-pcd-check-in-disable-command-state = "dsi_hs_mode";
	};

	timing@6{
		qcom,mdss-dsi-cmd-mode;
		qcom,mdss-dsi-panel-framerate = <120>;  /* Actually 1 hz*/
		qcom,mdss-dsi-panel-width = <1224>;
		qcom,mdss-dsi-panel-height = <2992>;
		qcom,mdss-dsi-h-front-porch = <21>;
		qcom,mdss-dsi-h-back-porch = <16>;
		qcom,mdss-dsi-h-pulse-width = <16>;
		qcom,mdss-dsi-h-sync-skew = <0>;
		qcom,mdss-dsi-h-sync-pulse = <0>;
		qcom,mdss-dsi-v-back-porch = <2>;
		qcom,mdss-dsi-v-front-porch = <2>;
		qcom,mdss-dsi-v-pulse-width = <2>;
		qcom,mdss-dsi-h-left-border = <0>;
		qcom,mdss-dsi-h-right-border = <0>;
		qcom,mdss-dsi-v-top-border = <0>;
		qcom,mdss-dsi-v-bottom-border = <0>;
	        qcom,mdss-dsi-panel-jitter = <0x20 0xa>;
		qcom,mdss-mdp-transfer-time-us = <7933>;
		qcom,mdss-dsi-timing-switch-command = [
			39 00 00 40 00 00 02 6B 00
			39 00 00 40 00 00 06 F0 55 AA 52 08 00
			39 00 00 40 00 00 02 6F CC
			39 00 00 40 00 00 02 B2 00 //exit MAFR
			39 00 00 40 00 00 02 6F 04
			39 00 00 40 00 00 02 35 00 //TE = 1
			39 00 00 40 00 00 02 53 20 //DBV Diming Enable
			39 00 00 40 00 00 02 5A 00
			39 00 00 40 00 00 02 6F 06
			39 00 00 40 00 00 02 6D 00
			39 00 00 40 00 00 02 2F 30
			39 00 00 40 00 00 03 6D 04 01
			39 00 00 40 00 00 02 6F 02
			39 00 00 40 00 00 02 8C 10
			39 00 00 00 00 00 02 8C 00
		];
		qcom,mdss-dsi-on-command = [
			39 00 00 40 00 00 06 F0 55 AA 52 08 00
			39 00 00 40 00 00 02 6F 04
			39 00 00 40 00 00 05 C6 33 A3 33 33
			39 00 00 40 00 00 06 F0 55 AA 52 08 01
			39 00 00 40 00 00 02 6F 2F
			39 00 00 40 00 00 02 C3 44
			39 00 00 40 00 00 02 6F 00
			39 00 00 40 00 00 02 C3 DD
			39 00 00 40 00 00 02 6F 04
			39 00 00 40 00 00 02 C3 07
			39 00 00 40 00 00 02 6F 09
			39 00 00 40 00 00 02 C3 07
			39 00 00 40 00 00 06 F0 55 AA 52 08 00
			39 00 00 40 00 00 02 6F 04
			39 00 00 40 00 00 02 B1 07
			39 00 00 40 00 00 02 68 20
			39 00 00 40 00 00 06 F0 55 AA 52 08 09
			39 00 00 40 00 00 02 BD 05
			39 00 00 40 00 00 02 6F 10
			39 00 00 40 00 00 02 C1 00
			39 00 00 40 00 00 02 6F 11
			39 00 00 40 00 00 03 C1 00 0A
			39 00 00 40 00 00 02 6F 13
			39 00 00 40 00 00 03 C1 00 00
			39 00 00 40 00 00 02 6F 00
			39 00 00 40 00 00 06 C6 8A 8D 8D 90 90
			39 00 00 40 00 00 02 6F 05
			39 00 00 40 00 00 06 C6 89 85 83 8A 8A
			39 00 00 40 00 00 02 6F 0A
			39 00 00 40 00 00 06 C6 8A 83 89 84 8A
			39 00 00 40 00 00 02 6F 0F
			39 00 00 40 00 00 06 C6 85 83 83 84 85
			39 00 00 40 00 00 02 6F 14
			39 00 00 40 00 00 06 C6 84 84 85 84 83
			39 00 00 40 00 00 02 6F 19
			39 00 00 40 00 00 06 C6 83 84 83 84 83
			39 00 00 40 00 00 02 6F 1E
			39 00 00 40 00 00 06 C6 8A 8D 8D 90 90
			39 00 00 40 00 00 02 6F 23
			39 00 00 40 00 00 06 C6 89 85 83 8A 8A
			39 00 00 40 00 00 02 6F 28
			39 00 00 40 00 00 06 C6 8A 83 89 84 8A
			39 00 00 40 00 00 02 6F 2D
			39 00 00 40 00 00 06 C6 85 83 83 84 85
			39 00 00 40 00 00 02 6F 32
			39 00 00 40 00 00 06 C6 84 84 85 84 83
			39 00 00 40 00 00 02 6F 37
			39 00 00 40 00 00 06 C6 83 84 83 84 83
			39 00 00 40 00 00 02 6F 3C
			39 00 00 40 00 00 06 C6 8A 8D 8D 90 90
			39 00 00 40 00 00 02 6F 41
			39 00 00 40 00 00 06 C6 89 85 83 8A 8A
			39 00 00 40 00 00 02 6F 46
			39 00 00 40 00 00 06 C6 85 83 89 84 8A
			39 00 00 40 00 00 02 6F 4B
			39 00 00 40 00 00 06 C6 8A 83 83 84 85
			39 00 00 40 00 00 02 6F 50
			39 00 00 40 00 00 06 C6 84 84 85 84 83
			39 00 00 40 00 00 02 6F 55
			39 00 00 40 00 00 06 C6 83 84 83 84 83
			39 00 00 40 00 00 06 F0 55 AA 52 08 00
			39 00 00 40 00 00 02 6F 0D
			39 00 00 40 00 00 02 C2 1A
			39 00 00 40 00 00 06 F0 55 AA 52 08 04
			39 00 00 40 00 00 02 B1 00
			39 00 00 40 00 00 02 6F 0A
			39 00 00 40 00 00 02 B1 20
			39 00 00 40 00 00 02 6F 07
			39 00 00 40 00 00 04 B1 00 00 00
			39 00 00 40 00 00 02 6F 0B
			39 00 00 40 00 00 02 B1 00
			39 00 00 40 00 00 02 6F 06
			39 00 00 40 00 00 02 8D 05
			39 00 00 40 00 00 02 6F 01
			39 00 00 40 00 00 02 8D 20
			39 00 00 40 00 00 02 5A 01
			39 00 00 40 00 00 06 F0 55 AA 52 08 00
			39 00 00 40 00 00 02 6F 31
			39 00 00 40 00 00 04 C0 00 23 00
			39 00 00 40 00 00 02 6F 35
			39 00 00 40 00 00 04 C0 44 41 44
			39 00 00 40 00 00 06 F0 55 AA 52 08 04
			39 00 00 40 00 00 02 C0 20
			39 00 00 40 00 00 05 FF AA 55 A5 80
			39 00 00 40 00 00 02 6F 07
			39 00 00 40 00 00 02 F8 4D
			39 00 00 40 00 00 02 6F 23
			39 00 00 40 00 00 02 F8 4D
			39 00 00 40 00 00 05 FF AA 55 A5 81
			39 00 00 40 00 00 02 6F 21
			39 00 00 40 00 00 02 F5 03
			39 00 00 40 00 00 02 6F 43
			39 00 00 40 00 00 19 F5 01 02 01 04 00 01 02 00 00 00 43 02 00 00 10 00 00 10 05 00 11 31 12 11
			39 00 00 40 00 00 02 6F 1D
			39 00 00 40 00 00 04 FB 64 07 80
			39 00 00 40 00 00 02 6F 07
			39 00 00 40 00 00 02 FC 04
			39 00 00 40 00 00 02 6F 30
			39 00 00 40 00 00 02 FE 20
			39 00 00 40 00 00 05 FF AA 55 A5 84
			39 00 00 40 00 00 02 6F 9A
			39 00 00 40 00 00 02 F3 0F
			39 00 00 40 00 00 02 6F 9F
			39 00 00 40 00 00 02 F4 00
			39 00 00 40 00 00 02 6F E9
			39 00 00 40 00 00 02 F4 03
			39 00 00 40 00 00 02 6F 28
			39 00 00 40 00 00 02 F8 00
			39 00 00 40 00 00 05 FF AA 55 A5 81
			39 00 00 40 00 00 02 6F 0F
			39 00 00 40 00 00 02 F5 0E
			39 00 00 40 00 00 06 F0 55 AA 52 08 00
			39 00 00 40 00 00 02 6F 78
			39 00 00 40 00 00 18 B0 10 00 2A 00 C2 01 DA 03 7C 05 B1 08 80 0B EE 0F FF 05 55 05 56 05 55
			39 00 00 40 00 00 02 6F 6F
			39 00 00 40 00 00 07 B0 02 64 04 C8 02 64
			39 00 00 40 00 00 06 F0 55 AA 52 08 08
			39 00 00 40 00 00 17 C1 8D FF DD FF FF DD FF FF DD FF FF DD FF FF EE FF FF AA 7C 1E 0E FF
			39 00 00 40 00 00 02 6F 23
			39 00 00 40 00 00 15 C1 0D FF DD FF FF DD FF FF DD FF FF DD FF FF EE FF FF AA 7C 1E
			39 00 00 40 00 00 02 6F 37
			39 00 00 40 00 00 15 C1 0D FF DD FF FF DD FF FF DD FF FF DD FF FF EE FF FF FF FF FF
			39 00 00 40 00 00 02 6F 4B
			39 00 00 40 00 00 15 C1 0D FF DD FF FF DD FF FF DD FF FF DD FF FF EE FF FF AA 7C 1E
			39 00 00 40 00 00 02 6F 5F
			39 00 00 40 00 00 15 C1 0D FF DD FF FF DD FF FF DD FF FF DD FF FF EE FF FF FF FF FF
			39 00 00 40 00 00 02 6F 73
			39 00 00 40 00 00 15 C1 0D FF DD FF FF DD FF FF DD FF FF DD FF FF EE FF FF AA 7C 1E
			39 00 00 40 00 00 11 BA 00 04 03 A4 03 A4 05 B8 05 B8 07 D8 07 D8 0A 84
			39 00 00 40 00 00 02 6F 10
			39 00 00 40 00 00 11 BA 0A 84 0D C3 0D C3 0D C4 0D C4 1D 24 1D 24 2C 50
			39 00 00 40 00 00 02 6F 20
			39 00 00 40 00 00 0d BA 2C 50 36 E8 36 E8 3A FE 3A FE 3F FC
			39 00 00 40 00 00 02 6F 20
			39 00 00 40 00 00 04 C1 04 52 CD
			39 00 00 40 00 00 02 6F 1D
			39 00 00 40 00 00 04 C1 00 80 FF
			39 00 00 40 00 00 02 6F 07
			39 00 00 40 00 00 02 51 00
			39 00 00 40 00 00 05 FF AA 55 A5 81
			39 00 00 40 00 00 02 6F 02
			39 00 00 40 00 00 02 F9 04
			39 00 00 40 00 00 05 FF AA 55 A5 81
			39 00 00 40 00 00 02 6F 0D
			39 00 00 40 00 00 02 FB 80
			39 00 00 40 00 00 05 FF AA 55 A5 81
			39 00 00 40 00 00 02 6F 10
			39 00 00 40 00 00 02 FB 40
			39 00 00 40 00 00 05 FF AA 55 A5 81
			39 00 00 40 00 00 02 6F 0C
			39 00 00 40 00 00 02 FD 08
			39 00 00 40 00 00 05 FF AA 55 A5 81
			39 00 00 40 00 00 02 6F 05
			39 00 00 40 00 00 03 FE 3C 3C
			39 00 00 40 00 00 05 FF AA 55 A5 80
			39 00 00 40 00 00 02 6F 0A
			39 00 00 40 00 00 06 F6 70 70 70 70 70
			39 00 00 40 00 00 05 2A 00 00 04 C7
			39 00 00 40 00 00 05 2B 00 00 0B AF
			39 00 00 40 00 00 02 5A 00
			39 00 00 40 00 00 02 6F 06
			39 00 00 40 00 00 02 6D 00
			39 00 00 40 00 00 02 2F 30
			39 00 00 40 00 00 03 6D 04 01
			39 00 00 40 00 00 02 6F 02
			39 00 00 40 00 00 02 8C 10
			39 00 00 40 00 00 02 8C 00
			39 00 00 40 00 00 03 5F 00 00
			39 00 00 40 00 00 02 35 00
			39 00 00 40 00 00 02 6F 04
			39 00 00 40 00 00 02 35 00
			39 00 00 40 00 00 03 51 00 00
			39 00 00 40 00 00 02 6F 04
			39 00 00 40 00 00 03 51 00 00
			39 00 00 40 00 00 02 53 20
			39 00 00 40 00 00 02 90 03
			39 00 00 40 00 00 02 6F 01
			39 00 00 40 00 00 02 90 43
			39 00 00 00 00 00 13 91 AB 28 00 10 C2 00 02 32 01 9C 00 08 06 67 05 9C 10 F0
                	05 00 00 00 78 00 01 11
                	05 00 00 00 00 00 01 29];	/* display on */
		qcom,mdss-dsi-off-command = [
			05 00 00 00 00 00 01 28		/* display_off */
			05 00 00 00 64 00 01 10];	/* enter sleep mode */

		qcom,mdss-dsi-on-command-state = "dsi_lp_mode";
		qcom,mdss-dsi-off-command-state = "dsi_lp_mode";
		qcom,mdss-dsi-timing-switch-command-state =
			"dsi_lp_mode";
		qcom,compression-mode = "dsc";
		/* Why QCOM doesn't use this, even it used 2 encoder
		 * as for that dsi_sw43404_amoled_cmd, for ex */
		/* qcom,mdss-dsc-encoders = <2>; */
		qcom,mdss-dsc-version = <0x11>;
		qcom,mdss-dsc-slice-height = <16>;
		qcom,mdss-dsc-slice-width = <612>;
		qcom,mdss-dsc-slice-per-pkt = <2>;
		qcom,mdss-dsc-bit-per-component = <10>;
		qcom,mdss-dsc-bit-per-pixel = <8>;
		qcom,mdss-dsc-block-prediction-enable;
		qcom,mdss-dsc-novateck-ic;
		qcom,mdss-dsi-pcd-check-in-enable-command = [
			39 00 00 40 00 00 06 F0 55 AA 52 08 01
			39 00 00 00 00 00 03 D0 00 80
			];
		qcom,mdss-dsi-pcd-check-in-enable-command-state = "dsi_hs_mode";
		qcom,mdss-dsi-pcd-check-in-disable-command = [
			39 00 00 40 00 00 06 F0 55 AA 52 08 01
			39 00 00 00 00 00 03 D0 00 00
			];
		qcom,mdss-dsi-pcd-check-in-disable-command-state = "dsi_hs_mode";
	};

	timing@7{
		qcom,mdss-dsi-cmd-mode;
		qcom,mdss-dsi-panel-framerate = <165>;
		qcom,mdss-dsi-panel-width = <1224>;
		qcom,mdss-dsi-panel-height = <2992>;
		qcom,mdss-dsi-h-front-porch = <25>;
		qcom,mdss-dsi-h-back-porch = <16>;
		qcom,mdss-dsi-h-pulse-width = <16>;
		qcom,mdss-dsi-h-sync-skew = <0>;
		qcom,mdss-dsi-h-sync-pulse = <0>;
		qcom,mdss-dsi-v-back-porch = <2>;
		qcom,mdss-dsi-v-front-porch = <2>;
		qcom,mdss-dsi-v-pulse-width = <2>;
		qcom,mdss-dsi-h-left-border = <0>;
		qcom,mdss-dsi-h-right-border = <0>;
		qcom,mdss-dsi-v-top-border = <0>;
		qcom,mdss-dsi-v-bottom-border = <0>;
	        qcom,mdss-dsi-panel-jitter = <0x20 0xa>;
		qcom,mdss-dsi-timing-switch-command = [
			39 00 00 40 00 00 02 6B 00
			39 00 00 40 00 00 06 F0 55 AA 52 08 00
			39 00 00 40 00 00 02 6F CC
			39 00 00 40 00 00 02 B2 00 //exit MAFR
			39 00 00 40 00 00 02 6F 02
			39 00 00 40 00 00 02 8C 10
			39 00 00 40 00 00 02 8C 00
			39 00 00 40 00 00 02 6F 04
			39 00 00 40 00 00 02 35 00 //TE1=0
			39 00 00 40 00 00 02 53 20 //DBV Diming Disable
			39 00 00 00 00 00 02 2F 03 //165hz
		];
		qcom,mdss-dsi-on-command = [
			39 00 00 40 00 00 06 F0 55 AA 52 08 00
			39 00 00 40 00 00 02 6F 04
			39 00 00 40 00 00 05 C6 33 A3 33 33
			39 00 00 40 00 00 06 F0 55 AA 52 08 01
			39 00 00 40 00 00 02 6F 2F
			39 00 00 40 00 00 02 C3 44
			39 00 00 40 00 00 02 6F 00
			39 00 00 40 00 00 02 C3 DD
			39 00 00 40 00 00 02 6F 04
			39 00 00 40 00 00 02 C3 07
			39 00 00 40 00 00 02 6F 09
			39 00 00 40 00 00 02 C3 07
			39 00 00 40 00 00 06 F0 55 AA 52 08 00
			39 00 00 40 00 00 02 6F 04
			39 00 00 40 00 00 02 B1 07
			39 00 00 40 00 00 02 68 20
			39 00 00 40 00 00 06 F0 55 AA 52 08 09
			39 00 00 40 00 00 02 BD 05
			39 00 00 40 00 00 02 6F 10
			39 00 00 40 00 00 02 C1 00
			39 00 00 40 00 00 02 6F 11
			39 00 00 40 00 00 03 C1 00 0A
			39 00 00 40 00 00 02 6F 13
			39 00 00 40 00 00 03 C1 00 00
			39 00 00 40 00 00 02 6F 00
			39 00 00 40 00 00 06 C6 8A 8D 8D 90 90
			39 00 00 40 00 00 02 6F 05
			39 00 00 40 00 00 06 C6 89 85 83 8A 8A
			39 00 00 40 00 00 02 6F 0A
			39 00 00 40 00 00 06 C6 8A 83 89 84 8A
			39 00 00 40 00 00 02 6F 0F
			39 00 00 40 00 00 06 C6 85 83 83 84 85
			39 00 00 40 00 00 02 6F 14
			39 00 00 40 00 00 06 C6 84 84 85 84 83
			39 00 00 40 00 00 02 6F 19
			39 00 00 40 00 00 06 C6 83 84 83 84 83
			39 00 00 40 00 00 02 6F 1E
			39 00 00 40 00 00 06 C6 8A 8D 8D 90 90
			39 00 00 40 00 00 02 6F 23
			39 00 00 40 00 00 06 C6 89 85 83 8A 8A
			39 00 00 40 00 00 02 6F 28
			39 00 00 40 00 00 06 C6 8A 83 89 84 8A
			39 00 00 40 00 00 02 6F 2D
			39 00 00 40 00 00 06 C6 85 83 83 84 85
			39 00 00 40 00 00 02 6F 32
			39 00 00 40 00 00 06 C6 84 84 85 84 83
			39 00 00 40 00 00 02 6F 37
			39 00 00 40 00 00 06 C6 83 84 83 84 83
			39 00 00 40 00 00 02 6F 3C
			39 00 00 40 00 00 06 C6 8A 8D 8D 90 90
			39 00 00 40 00 00 02 6F 41
			39 00 00 40 00 00 06 C6 89 85 83 8A 8A
			39 00 00 40 00 00 02 6F 46
			39 00 00 40 00 00 06 C6 85 83 89 84 8A
			39 00 00 40 00 00 02 6F 4B
			39 00 00 40 00 00 06 C6 8A 83 83 84 85
			39 00 00 40 00 00 02 6F 50
			39 00 00 40 00 00 06 C6 84 84 85 84 83
			39 00 00 40 00 00 02 6F 55
			39 00 00 40 00 00 06 C6 83 84 83 84 83
			39 00 00 40 00 00 06 F0 55 AA 52 08 00
			39 00 00 40 00 00 02 6F 0D
			39 00 00 40 00 00 02 C2 1A
			39 00 00 40 00 00 06 F0 55 AA 52 08 04
			39 00 00 40 00 00 02 B1 00
			39 00 00 40 00 00 02 6F 0A
			39 00 00 40 00 00 02 B1 20
			39 00 00 40 00 00 02 6F 07
			39 00 00 40 00 00 04 B1 00 00 00
			39 00 00 40 00 00 02 6F 0B
			39 00 00 40 00 00 02 B1 00
			39 00 00 40 00 00 02 6F 06
			39 00 00 40 00 00 02 8D 05
			39 00 00 40 00 00 02 6F 01
			39 00 00 40 00 00 02 8D 20
			39 00 00 40 00 00 02 5A 01
			39 00 00 40 00 00 06 F0 55 AA 52 08 00
			39 00 00 40 00 00 02 6F 31
			39 00 00 40 00 00 04 C0 00 23 00
			39 00 00 40 00 00 02 6F 35
			39 00 00 40 00 00 04 C0 44 41 44
			39 00 00 40 00 00 06 F0 55 AA 52 08 04
			39 00 00 40 00 00 02 C0 20
			39 00 00 40 00 00 05 FF AA 55 A5 80
			39 00 00 40 00 00 02 6F 07
			39 00 00 40 00 00 02 F8 4D
			39 00 00 40 00 00 02 6F 23
			39 00 00 40 00 00 02 F8 4D
			39 00 00 40 00 00 05 FF AA 55 A5 81
			39 00 00 40 00 00 02 6F 21
			39 00 00 40 00 00 02 F5 03
			39 00 00 40 00 00 02 6F 43
			39 00 00 40 00 00 19 F5 01 02 01 04 00 01 02 00 00 00 43 02 00 00 10 00 00 10 05 00 11 31 12 11
			39 00 00 40 00 00 02 6F 1D
			39 00 00 40 00 00 04 FB 64 07 80
			39 00 00 40 00 00 02 6F 07
			39 00 00 40 00 00 02 FC 04
			39 00 00 40 00 00 02 6F 30
			39 00 00 40 00 00 02 FE 20
			39 00 00 40 00 00 05 FF AA 55 A5 84
			39 00 00 40 00 00 02 6F 9A
			39 00 00 40 00 00 02 F3 0F
			39 00 00 40 00 00 02 6F 9F
			39 00 00 40 00 00 02 F4 00
			39 00 00 40 00 00 02 6F E9
			39 00 00 40 00 00 02 F4 03
			39 00 00 40 00 00 02 6F 28
			39 00 00 40 00 00 02 F8 00
			39 00 00 40 00 00 05 FF AA 55 A5 81
			39 00 00 40 00 00 02 6F 0F
			39 00 00 40 00 00 02 F5 0E
			39 00 00 40 00 00 06 F0 55 AA 52 08 00
			39 00 00 40 00 00 02 6F 78
			39 00 00 40 00 00 18 B0 10 00 2A 00 C2 01 DA 03 7C 05 B1 08 80 0B EE 0F FF 05 55 05 56 05 55
			39 00 00 40 00 00 02 6F 6F
			39 00 00 40 00 00 07 B0 02 64 04 C8 02 64
			39 00 00 40 00 00 06 F0 55 AA 52 08 08
			39 00 00 40 00 00 17 C1 8D FF DD FF FF DD FF FF DD FF FF DD FF FF EE FF FF AA 7C 1E 0E FF
			39 00 00 40 00 00 02 6F 23
			39 00 00 40 00 00 15 C1 0D FF DD FF FF DD FF FF DD FF FF DD FF FF EE FF FF AA 7C 1E
			39 00 00 40 00 00 02 6F 37
			39 00 00 40 00 00 15 C1 0D FF DD FF FF DD FF FF DD FF FF DD FF FF EE FF FF FF FF FF
			39 00 00 40 00 00 02 6F 4B
			39 00 00 40 00 00 15 C1 0D FF DD FF FF DD FF FF DD FF FF DD FF FF EE FF FF AA 7C 1E
			39 00 00 40 00 00 02 6F 5F
			39 00 00 40 00 00 15 C1 0D FF DD FF FF DD FF FF DD FF FF DD FF FF EE FF FF FF FF FF
			39 00 00 40 00 00 02 6F 73
			39 00 00 40 00 00 15 C1 0D FF DD FF FF DD FF FF DD FF FF DD FF FF EE FF FF AA 7C 1E
			39 00 00 40 00 00 11 BA 00 04 03 A4 03 A4 05 B8 05 B8 07 D8 07 D8 0A 84
			39 00 00 40 00 00 02 6F 10
			39 00 00 40 00 00 11 BA 0A 84 0D C3 0D C3 0D C4 0D C4 1D 24 1D 24 2C 50
			39 00 00 40 00 00 02 6F 20
			39 00 00 40 00 00 0d BA 2C 50 36 E8 36 E8 3A FE 3A FE 3F FC
			39 00 00 40 00 00 02 6F 20
			39 00 00 40 00 00 04 C1 04 52 CD
			39 00 00 40 00 00 02 6F 1D
			39 00 00 40 00 00 04 C1 00 80 FF
			39 00 00 40 00 00 02 6F 07
			39 00 00 40 00 00 02 51 00
			39 00 00 40 00 00 05 FF AA 55 A5 81
			39 00 00 40 00 00 02 6F 02
			39 00 00 40 00 00 02 F9 04
			39 00 00 40 00 00 05 FF AA 55 A5 81
			39 00 00 40 00 00 02 6F 0D
			39 00 00 40 00 00 02 FB 80
			39 00 00 40 00 00 05 FF AA 55 A5 81
			39 00 00 40 00 00 02 6F 10
			39 00 00 40 00 00 02 FB 40
			39 00 00 40 00 00 05 FF AA 55 A5 81
			39 00 00 40 00 00 02 6F 0C
			39 00 00 40 00 00 02 FD 08
			39 00 00 40 00 00 05 FF AA 55 A5 81
			39 00 00 40 00 00 02 6F 05
			39 00 00 40 00 00 03 FE 3C 3C
			39 00 00 40 00 00 05 FF AA 55 A5 80
			39 00 00 40 00 00 02 6F 0A
			39 00 00 40 00 00 06 F6 70 70 70 70 70
			39 00 00 40 00 00 05 2A 00 00 04 C7
			39 00 00 40 00 00 05 2B 00 00 0B AF
			39 00 00 40 00 00 02 2F 03
			39 00 00 40 00 00 03 5F 00 00
			39 00 00 40 00 00 02 35 00
			39 00 00 40 00 00 02 6F 02
			39 00 00 40 00 00 02 8C 10
			39 00 00 40 00 00 02 8C 00
			39 00 00 40 00 00 02 6F 04
			39 00 00 40 00 00 02 35 00
			39 00 00 40 00 00 03 51 00 00
			39 00 00 40 00 00 02 6F 04
			39 00 00 40 00 00 03 51 00 00
			39 00 00 40 00 00 02 53 20
			39 00 00 40 00 00 02 90 03
			39 00 00 40 00 00 02 6F 01
			39 00 00 40 00 00 02 90 43
			39 00 00 00 00 00 13 91 AB 28 00 10 C2 00 02 32 01 9C 00 08 06 67 05 9C 10 F0
                	05 00 00 00 78 00 01 11
                	05 00 00 00 00 00 01 29];	/* display on */
		qcom,mdss-dsi-off-command = [
			05 00 00 00 00 00 01 28		/* display_off */
			05 00 00 00 64 00 01 10];	/* enter sleep mode */

		qcom,mdss-dsi-on-command-state = "dsi_lp_mode";
		qcom,mdss-dsi-off-command-state = "dsi_lp_mode";
		qcom,mdss-dsi-timing-switch-command-state =
			"dsi_lp_mode";
		qcom,compression-mode = "dsc";
		/* Why QCOM doesn't use this, even it used 2 encoder
		 * as for that dsi_sw43404_amoled_cmd, for ex */
		/* qcom,mdss-dsc-encoders = <2>; */
		qcom,mdss-dsc-version = <0x11>;
		qcom,mdss-dsc-slice-height = <16>;
		qcom,mdss-dsc-slice-width = <612>;
		qcom,mdss-dsc-slice-per-pkt = <2>;
		qcom,mdss-dsc-bit-per-component = <10>;
		qcom,mdss-dsc-bit-per-pixel = <8>;
		qcom,mdss-dsc-block-prediction-enable;
		qcom,mdss-dsc-novateck-ic;
		qcom,mdss-dsi-pcd-check-in-enable-command = [
			39 00 00 40 00 00 06 F0 55 AA 52 08 01
			39 00 00 00 00 00 03 D0 00 80
			];
		qcom,mdss-dsi-pcd-check-in-enable-command-state = "dsi_hs_mode";
		qcom,mdss-dsi-pcd-check-in-disable-command = [
			39 00 00 40 00 00 06 F0 55 AA 52 08 01
			39 00 00 00 00 00 03 D0 00 00
			];
		qcom,mdss-dsi-pcd-check-in-disable-command-state = "dsi_hs_mode";
		qcom,mdss-dsi-lp1-command = [
			39 00 00 40 00 00 02 6B 00
			39 00 00 40 00 00 06 F0 55 AA 52 08 00
			39 00 00 40 00 00 02 6F CC
			39 00 00 40 00 00 02 B2 00 //exit MAFR
			39 00 00 40 00 00 02 6F 02
			39 00 00 40 00 00 02 8C 10
			39 00 00 40 00 00 02 8C 00
			39 00 00 40 00 00 02 6F 04
			39 00 00 40 00 00 02 35 00 //TE1=0
			39 00 00 40 00 00 02 53 20 //DBV Diming Disable
			39 00 00 00 00 00 02 2F 03 //165hz
		];
		qcom,mdss-dsi-lp1-command-state =
			"dsi_lp_mode";
		qcom,mdss-dsi-lp2-command = [
			39 00 00 40 00 00 02 6B 00
			39 00 00 40 00 00 06 F0 55 AA 52 08 00
			39 00 00 40 00 00 02 6F CC
			39 00 00 40 00 00 02 B2 00 //exit MAFR
			39 00 00 40 00 00 02 6F 04
			39 00 00 40 00 00 02 35 00 //TE = 1
			39 00 00 40 00 00 02 53 20 //DBV Diming Enable
			39 00 00 40 00 00 02 5A 00
			39 00 00 40 00 00 02 6F 06
			39 00 00 40 00 00 02 6D 00
			39 00 00 40 00 00 02 2F 30
			39 00 00 40 00 00 03 6D 04 00
			39 00 00 40 00 00 02 6F 02
			39 00 00 40 00 00 02 8C 10
			39 00 00 00 00 00 02 8C 00
		];
		qcom,mdss-dsi-lp2-command-state =
			"dsi_lp_mode";
		qcom,mdss-dsi-nolp-command = [
			39 00 00 40 00 00 02 6B 00
			39 00 00 40 00 00 06 F0 55 AA 52 08 00
			39 00 00 40 00 00 02 6F CC
			39 00 00 40 00 00 02 B2 00 //exit MAFR
			39 00 00 40 00 00 02 6F 02
			39 00 00 40 00 00 02 8C 10
			39 00 00 40 00 00 02 8C 00
			39 00 00 40 00 00 02 6F 04
			39 00 00 40 00 00 02 35 00 //TE1=0
			39 00 00 40 00 00 02 53 20 //DBV Diming Disable
			39 00 00 00 00 00 02 2F 03 //165hz
		];
		qcom,mdss-dsi-nolp-command-state =
			"dsi_lp_mode";
	};

	timing@8{
		qcom,mdss-dsi-cmd-mode;
		/* Actually 10-60-10 hz*/
		qcom,mdss-dsi-panel-framerate = <60>;
		qcom,mdss-dsi-panel-width = <1224>;
		qcom,mdss-dsi-panel-height = <2992>;
		qcom,mdss-dsi-h-front-porch = <20>;
		qcom,mdss-dsi-h-back-porch = <16>;
		qcom,mdss-dsi-h-pulse-width = <16>;
		qcom,mdss-dsi-h-sync-skew = <0>;
		qcom,mdss-dsi-h-sync-pulse = <0>;
		qcom,mdss-dsi-v-back-porch = <2>;
		qcom,mdss-dsi-v-front-porch = <2>;
		qcom,mdss-dsi-v-pulse-width = <2>;
		qcom,mdss-dsi-h-left-border = <0>;
		qcom,mdss-dsi-h-right-border = <0>;
		qcom,mdss-dsi-v-top-border = <0>;
		qcom,mdss-dsi-v-bottom-border = <0>;
	        qcom,mdss-dsi-panel-jitter = <0x20 0xa>;
		qcom,mdss-dsi-timing-switch-command = [
			39 00 00 40 00 00 02 6B 00
			39 00 00 40 00 00 06 F0 55 AA 52 08 00
			39 00 00 40 00 00 02 6F CC
			39 00 00 40 00 00 02 B2 01
			39 00 00 40 00 00 02 5A 00
			39 00 00 40 00 00 02 6B 00
			39 00 00 40 00 00 02 2F 01
			39 00 00 40 00 00 02 6F 01
			39 00 00 40 00 00 05 6B 03 E8 07 D0
			39 00 00 40 00 00 02 6F 10
			39 00 00 40 00 00 0f 6B 01 05 01 01 05 01 01 05 01 01 05 01 01 05
			39 00 00 40 00 00 02 6F 20
			39 00 00 40 00 00 0f 6B 01 00 01 01 00 01 01 00 01 01 00 01 01 00
			39 00 00 40 00 00 02 6F 30
			39 00 00 40 00 00 0f 6B 01 05 01 01 05 01 01 05 01 01 05 01 01 05
			39 00 00 00 11 00 02 6B 01
		];
		qcom,mdss-dsi-on-command = [
			39 00 00 40 00 00 06 F0 55 AA 52 08 00
			39 00 00 40 00 00 02 6F 04
			39 00 00 40 00 00 05 C6 33 A3 33 33
			39 00 00 40 00 00 06 F0 55 AA 52 08 01
			39 00 00 40 00 00 02 6F 2F
			39 00 00 40 00 00 02 C3 44
			39 00 00 40 00 00 02 6F 00
			39 00 00 40 00 00 02 C3 DD
			39 00 00 40 00 00 02 6F 04
			39 00 00 40 00 00 02 C3 07
			39 00 00 40 00 00 02 6F 09
			39 00 00 40 00 00 02 C3 07
			39 00 00 40 00 00 06 F0 55 AA 52 08 00
			39 00 00 40 00 00 02 6F 04
			39 00 00 40 00 00 02 B1 07
			39 00 00 40 00 00 02 68 20
			39 00 00 40 00 00 06 F0 55 AA 52 08 09
			39 00 00 40 00 00 02 BD 05
			39 00 00 40 00 00 02 6F 10
			39 00 00 40 00 00 02 C1 00
			39 00 00 40 00 00 02 6F 11
			39 00 00 40 00 00 03 C1 00 0A
			39 00 00 40 00 00 02 6F 13
			39 00 00 40 00 00 03 C1 00 00
			39 00 00 40 00 00 02 6F 00
			39 00 00 40 00 00 06 C6 8A 8D 8D 90 90
			39 00 00 40 00 00 02 6F 05
			39 00 00 40 00 00 06 C6 89 85 83 8A 8A
			39 00 00 40 00 00 02 6F 0A
			39 00 00 40 00 00 06 C6 8A 83 89 84 8A
			39 00 00 40 00 00 02 6F 0F
			39 00 00 40 00 00 06 C6 85 83 83 84 85
			39 00 00 40 00 00 02 6F 14
			39 00 00 40 00 00 06 C6 84 84 85 84 83
			39 00 00 40 00 00 02 6F 19
			39 00 00 40 00 00 06 C6 83 84 83 84 83
			39 00 00 40 00 00 02 6F 1E
			39 00 00 40 00 00 06 C6 8A 8D 8D 90 90
			39 00 00 40 00 00 02 6F 23
			39 00 00 40 00 00 06 C6 89 85 83 8A 8A
			39 00 00 40 00 00 02 6F 28
			39 00 00 40 00 00 06 C6 8A 83 89 84 8A
			39 00 00 40 00 00 02 6F 2D
			39 00 00 40 00 00 06 C6 85 83 83 84 85
			39 00 00 40 00 00 02 6F 32
			39 00 00 40 00 00 06 C6 84 84 85 84 83
			39 00 00 40 00 00 02 6F 37
			39 00 00 40 00 00 06 C6 83 84 83 84 83
			39 00 00 40 00 00 02 6F 3C
			39 00 00 40 00 00 06 C6 8A 8D 8D 90 90
			39 00 00 40 00 00 02 6F 41
			39 00 00 40 00 00 06 C6 89 85 83 8A 8A
			39 00 00 40 00 00 02 6F 46
			39 00 00 40 00 00 06 C6 85 83 89 84 8A
			39 00 00 40 00 00 02 6F 4B
			39 00 00 40 00 00 06 C6 8A 83 83 84 85
			39 00 00 40 00 00 02 6F 50
			39 00 00 40 00 00 06 C6 84 84 85 84 83
			39 00 00 40 00 00 02 6F 55
			39 00 00 40 00 00 06 C6 83 84 83 84 83
			39 00 00 40 00 00 06 F0 55 AA 52 08 00
			39 00 00 40 00 00 02 6F 0D
			39 00 00 40 00 00 02 C2 1A
			39 00 00 40 00 00 06 F0 55 AA 52 08 04
			39 00 00 40 00 00 02 B1 00
			39 00 00 40 00 00 02 6F 0A
			39 00 00 40 00 00 02 B1 20
			39 00 00 40 00 00 02 6F 07
			39 00 00 40 00 00 04 B1 00 00 00
			39 00 00 40 00 00 02 6F 0B
			39 00 00 40 00 00 02 B1 00
			39 00 00 40 00 00 02 6F 06
			39 00 00 40 00 00 02 8D 05
			39 00 00 40 00 00 02 6F 01
			39 00 00 40 00 00 02 8D 20
			39 00 00 40 00 00 02 5A 01
			39 00 00 40 00 00 06 F0 55 AA 52 08 00
			39 00 00 40 00 00 02 6F 31
			39 00 00 40 00 00 04 C0 00 23 00
			39 00 00 40 00 00 02 6F 35
			39 00 00 40 00 00 04 C0 44 41 44
			39 00 00 40 00 00 06 F0 55 AA 52 08 04
			39 00 00 40 00 00 02 C0 20
			39 00 00 40 00 00 05 FF AA 55 A5 80
			39 00 00 40 00 00 02 6F 07
			39 00 00 40 00 00 02 F8 4D
			39 00 00 40 00 00 02 6F 23
			39 00 00 40 00 00 02 F8 4D
			39 00 00 40 00 00 05 FF AA 55 A5 81
			39 00 00 40 00 00 02 6F 21
			39 00 00 40 00 00 02 F5 03
			39 00 00 40 00 00 02 6F 43
			39 00 00 40 00 00 19 F5 01 02 01 04 00 01 02 00 00 00 43 02 00 00 10 00 00 10 05 00 11 31 12 11
			39 00 00 40 00 00 02 6F 1D
			39 00 00 40 00 00 04 FB 64 07 80
			39 00 00 40 00 00 02 6F 07
			39 00 00 40 00 00 02 FC 04
			39 00 00 40 00 00 02 6F 30
			39 00 00 40 00 00 02 FE 20
			39 00 00 40 00 00 05 FF AA 55 A5 84
			39 00 00 40 00 00 02 6F 9A
			39 00 00 40 00 00 02 F3 0F
			39 00 00 40 00 00 02 6F 9F
			39 00 00 40 00 00 02 F4 00
			39 00 00 40 00 00 02 6F E9
			39 00 00 40 00 00 02 F4 03
			39 00 00 40 00 00 02 6F 28
			39 00 00 40 00 00 02 F8 00
			39 00 00 40 00 00 05 FF AA 55 A5 81
			39 00 00 40 00 00 02 6F 0F
			39 00 00 40 00 00 02 F5 0E
			39 00 00 40 00 00 06 F0 55 AA 52 08 00
			39 00 00 40 00 00 02 6F 78
			39 00 00 40 00 00 18 B0 10 00 2A 00 C2 01 DA 03 7C 05 B1 08 80 0B EE 0F FF 05 55 05 56 05 55
			39 00 00 40 00 00 02 6F 6F
			39 00 00 40 00 00 07 B0 02 64 04 C8 02 64
			39 00 00 40 00 00 06 F0 55 AA 52 08 08
			39 00 00 40 00 00 17 C1 8D FF DD FF FF DD FF FF DD FF FF DD FF FF EE FF FF AA 7C 1E 0E FF
			39 00 00 40 00 00 02 6F 23
			39 00 00 40 00 00 15 C1 0D FF DD FF FF DD FF FF DD FF FF DD FF FF EE FF FF AA 7C 1E
			39 00 00 40 00 00 02 6F 37
			39 00 00 40 00 00 15 C1 0D FF DD FF FF DD FF FF DD FF FF DD FF FF EE FF FF FF FF FF
			39 00 00 40 00 00 02 6F 4B
			39 00 00 40 00 00 15 C1 0D FF DD FF FF DD FF FF DD FF FF DD FF FF EE FF FF AA 7C 1E
			39 00 00 40 00 00 02 6F 5F
			39 00 00 40 00 00 15 C1 0D FF DD FF FF DD FF FF DD FF FF DD FF FF EE FF FF FF FF FF
			39 00 00 40 00 00 02 6F 73
			39 00 00 40 00 00 15 C1 0D FF DD FF FF DD FF FF DD FF FF DD FF FF EE FF FF AA 7C 1E
			39 00 00 40 00 00 11 BA 00 04 03 A4 03 A4 05 B8 05 B8 07 D8 07 D8 0A 84
			39 00 00 40 00 00 02 6F 10
			39 00 00 40 00 00 11 BA 0A 84 0D C3 0D C3 0D C4 0D C4 1D 24 1D 24 2C 50
			39 00 00 40 00 00 02 6F 20
			39 00 00 40 00 00 0d BA 2C 50 36 E8 36 E8 3A FE 3A FE 3F FC
			39 00 00 40 00 00 02 6F 20
			39 00 00 40 00 00 04 C1 04 52 CD
			39 00 00 40 00 00 02 6F 1D
			39 00 00 40 00 00 04 C1 00 80 FF
			39 00 00 40 00 00 02 6F 07
			39 00 00 40 00 00 02 51 00
			39 00 00 40 00 00 05 FF AA 55 A5 81
			39 00 00 40 00 00 02 6F 02
			39 00 00 40 00 00 02 F9 04
			39 00 00 40 00 00 05 FF AA 55 A5 81
			39 00 00 40 00 00 02 6F 0D
			39 00 00 40 00 00 02 FB 80
			39 00 00 40 00 00 05 FF AA 55 A5 81
			39 00 00 40 00 00 02 6F 10
			39 00 00 40 00 00 02 FB 40
			39 00 00 40 00 00 05 FF AA 55 A5 81
			39 00 00 40 00 00 02 6F 0C
			39 00 00 40 00 00 02 FD 08
			39 00 00 40 00 00 05 FF AA 55 A5 81
			39 00 00 40 00 00 02 6F 05
			39 00 00 40 00 00 03 FE 3C 3C
			39 00 00 40 00 00 05 FF AA 55 A5 80
			39 00 00 40 00 00 02 6F 0A
			39 00 00 40 00 00 06 F6 70 70 70 70 70
			39 00 00 40 00 00 05 2A 00 00 04 C7
			39 00 00 40 00 00 05 2B 00 00 0B AF
			39 00 00 40 00 00 02 2F 02
			39 00 00 40 00 00 03 5F 00 00
			39 00 00 40 00 00 02 35 00
			39 00 00 40 00 00 02 6F 02
			39 00 00 40 00 00 02 8C 10
			39 00 00 40 00 00 02 8C 00
			39 00 00 40 00 00 02 6F 04
			39 00 00 40 00 00 02 35 00
			39 00 00 40 00 00 03 51 00 00
			39 00 00 40 00 00 02 6F 04
			39 00 00 40 00 00 03 51 00 00
			39 00 00 40 00 00 02 53 20
			39 00 00 40 00 00 02 90 03
			39 00 00 40 00 00 02 6F 01
			39 00 00 40 00 00 02 90 43
			39 00 00 00 00 00 13 91 AB 28 00 10 C2 00 02 32 01 9C 00 08 06 67 05 9C 10 F0
                	05 00 00 00 78 00 01 11
			05 00 00 00 00 00 01 29];	/* display on */
		qcom,mdss-dsi-off-command = [
			05 00 00 00 00 00 01 28		/* display_off */
			05 00 00 00 64 00 01 10];	/* enter sleep mode */

		qcom,mdss-dsi-on-command-state = "dsi_lp_mode";
		qcom,mdss-dsi-off-command-state = "dsi_lp_mode";
		qcom,mdss-dsi-timing-switch-command-state =
			"dsi_lp_mode";
		qcom,compression-mode = "dsc";
		/* Why QCOM doesn't use this, even it used 2 encoder
		 * as for that dsi_sw43404_amoled_cmd, for ex */
		/* qcom,mdss-dsc-encoders = <2>; */
		qcom,mdss-dsc-version = <0x11>;
		qcom,mdss-dsc-slice-height = <16>;
		qcom,mdss-dsc-slice-width = <612>;
		qcom,mdss-dsc-slice-per-pkt = <2>;
		qcom,mdss-dsc-bit-per-component = <10>;
		qcom,mdss-dsc-bit-per-pixel = <8>;
		qcom,mdss-dsc-block-prediction-enable;
		qcom,mdss-dsc-novateck-ic;
		qcom,mdss-dsi-pcd-check-in-enable-command = [
			39 00 00 40 00 00 06 F0 55 AA 52 08 01
			39 00 00 00 00 00 03 D0 00 80
			];
		qcom,mdss-dsi-pcd-check-in-enable-command-state = "dsi_hs_mode";
		qcom,mdss-dsi-pcd-check-in-disable-command = [
			39 00 00 40 00 00 06 F0 55 AA 52 08 01
			39 00 00 00 00 00 03 D0 00 00
			];
		qcom,mdss-dsi-pcd-check-in-disable-command-state = "dsi_hs_mode";
		qcom,mdss-dsi-partition-refreshrate-off-command = [
			39 00 00 00 00 00 02 6B 00
			39 00 00 40 00 00 06 F0 55 AA 52 08 00
			39 00 00 40 00 00 02 6F CC
			39 00 00 00 00 00 02 B2 00
		];

		qcom,mdss-dsi-partition-refreshrate-off-command-state = "dsi_hs_mode";
		qcom,mdss-dsi-partition-refreshrate-on-command = [
			39 00 00 40 00 00 02 6B 00
			39 00 00 40 00 00 06 F0 55 AA 52 08 00
			39 00 00 40 00 00 02 6F CC
			39 00 00 40 00 00 02 B2 01
			39 00 00 40 00 00 02 5A 00
			39 00 00 40 00 00 02 6B 00
			39 00 00 40 00 00 02 2F 01
			39 00 00 40 00 00 02 6F 01
			39 00 00 40 00 00 05 6B 03 E8 07 D0
			39 00 00 40 00 00 02 6F 10
			39 00 00 40 00 00 0f 6B 01 05 01 01 05 01 01 05 01 01 05 01 01 05
			39 00 00 40 00 00 02 6F 20
			39 00 00 40 00 00 0f 6B 01 00 01 01 00 01 01 00 01 01 00 01 01 00
			39 00 00 40 00 00 02 6F 30
			39 00 00 40 00 00 0f 6B 01 05 01 01 05 01 01 05 01 01 05 01 01 05
			39 00 00 00 11 00 02 6B 01
		];
		qcom,mdss-dsi-partition-refreshrate-on-command-state = "dsi_hs_mode";

	};
};

};

};

